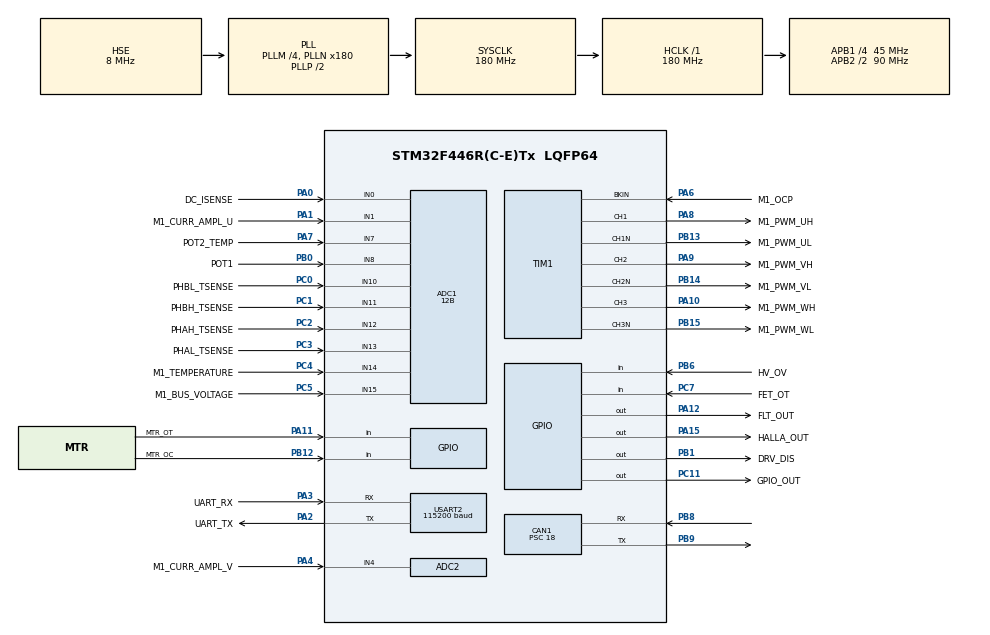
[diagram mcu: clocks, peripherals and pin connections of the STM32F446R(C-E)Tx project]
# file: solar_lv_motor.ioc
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ADC1.Channel-1\#ChannelInjectedConversion=ADC_CHANNEL_1
ADC1.Channel-1\#ChannelRegularConversion=ADC_CHANNEL_15
ADC1.Channel-2\#ChannelRegularConversion=ADC_CHANNEL_14
ADC1.ClockPrescaler=ADC_CLOCK_SYNC_PCLK_DIV4
ADC1.ContinuousConvMode=DISABLE
ADC1.DMAContinuousRequests=DISABLE
ADC1.DataAlign=ADC_DATAALIGN_LEFT
ADC1.DiscontinuousConvMode=DISABLE
ADC1.EOCSelection=ADC_EOC_SINGLE_CONV
ADC1.EnableAnalogWatchDog=false
ADC1.ExternalTrigConv=ADC_SOFTWARE_START
ADC1.ExternalTrigConvEdge=ADC_EXTERNALTRIGCONVEDGE_NONE
ADC1.ExternalTrigInjecConv=ADC_EXTERNALTRIGINJECCONV_T1_CC4
ADC1.ExternalTrigInjecConvEdge=ADC_EXTERNALTRIGINJECCONVEDGE_RISING
ADC1.InjNumberOfConversion=1
ADC1.InjectedConvMode=None
ADC1.InjectedOffset-1\#ChannelInjectedConversion=0
ADC1.InjectedRank-1\#ChannelInjectedConversion=1
ADC1.NbrOfConversion=2
ADC1.NbrOfConversionFlag=1
ADC1.Rank-1\#ChannelRegularConversion=1
ADC1.Rank-2\#ChannelRegularConversion=2
ADC1.Resolution=ADC_RESOLUTION_12B
ADC1.SamplingTime-1\#ChannelInjectedConversion=ADC_SAMPLETIME_15CYCLES
ADC1.SamplingTime-1\#ChannelRegularConversion=ADC_SAMPLETIME_3CYCLES
ADC1.SamplingTime-2\#ChannelRegularConversion=ADC_SAMPLETIME_28CYCLES
ADC1.ScanConvMode=ENABLE
ADC1.master=1
ADC2.Channel-1\#ChannelInjectedConversion=ADC_CHANNEL_4
ADC2.Channel-1\#ChannelRegularConversion=ADC_CHANNEL_4
ADC2.ClockPrescaler=ADC_CLOCK_SYNC_PCLK_DIV4
ADC2.ContinuousConvMode=DISABLE
ADC2.DMAContinuousRequests=DISABLE
ADC2.DataAlign=ADC_DATAALIGN_LEFT
ADC2.DiscontinuousConvMode=DISABLE
ADC2.EOCSelection=ADC_EOC_SINGLE_CONV
ADC2.EnableAnalogWatchDog=false
ADC2.ExternalTrigConv=ADC_SOFTWARE_START
ADC2.ExternalTrigConvEdge=ADC_EXTERNALTRIGCONVEDGE_NONE
ADC2.ExternalTrigInjecConv=ADC_EXTERNALTRIGINJECCONV_T1_CC4
ADC2.ExternalTrigInjecConvEdge=ADC_EXTERNALTRIGINJECCONVEDGE_RISING
ADC2.InjNumberOfConversion=1
ADC2.InjectedConvMode=None
ADC2.InjectedOffset-1\#ChannelInjectedConversion=0
ADC2.InjectedRank-1\#ChannelInjectedConversion=1
ADC2.NbrOfConversion=1
ADC2.NbrOfConversionFlag=1
ADC2.Rank-1\#ChannelRegularConversion=1
ADC2.Resolution=ADC_RESOLUTION_12B
ADC2.SamplingTime-1\#ChannelInjectedConversion=ADC_SAMPLETIME_15CYCLES
ADC2.SamplingTime-1\#ChannelRegularConversion=ADC_SAMPLETIME_15CYCLES
ADC2.ScanConvMode=ENABLE
CAN1.BS1=CAN_BS1_2TQ
CAN1.BS2=CAN_BS2_2TQ
CAN1.CalculateBaudRate=500000
CAN1.CalculateTimeBit=2000
CAN1.CalculateTimeQuantum=400.0
CAN1.Mode=CAN_MODE_NORMAL
CAN1.NART=DISABLE
CAN1.Prescaler=18
ExtraMW=MotorControl
ExtraMW.MotorControl.Config=MotorControl
ExtraMW.MotorControl.Mode=MotorControl
ExtraMW.MotorControl.Root=MCSDK_v5.4.8/MotorControl
ExtraMW.MotorControl.Template=templates
Mcu.Family=STM32F4
Mcu.Name=STM32F446R(C-E)Tx
Mcu.Package=LQFP64
MotorControl.ADC_1_PERIPH=ADC1
MotorControl.ADC_2_PERIPH=ADC2
MotorControl.ADC_AHBPERIPH=RCC_AHBPeriph_ADC12
MotorControl.ADC_CLOCK_WB_DIV=1
MotorControl.ADC_CLOCK_WB_FREQ=22.5
MotorControl.ADC_PERIPH=ADC1
MotorControl.ADC_REFERENCE_VOLTAGE=3.30
MotorControl.ALIGNMENT_ANGLE_DEG=90
MotorControl.ALIGNMENT_DURATION=700
MotorControl.AMPLIFICATION_GAIN=0.077
MotorControl.ANGC={0,0,0,0,0,0,0,0}
MotorControl.BEMF_CONSISTENCY_GAIN=64
MotorControl.BEMF_CONSISTENCY_TOL=64
MotorControl.BKIN1_FILTER=0
MotorControl.BKIN2_FILTER=0
MotorControl.BKIN2_MODE=NONE
MotorControl.BKIN_MODE=EXT_MODE
MotorControl.BOARD=CUSTOM
MotorControl.BRKIN2_GPIO_AF=GPIO_AF_2
MotorControl.BRKIN_GPIO_AF=GPIO_AF_2
MotorControl.BUS_VOLTAGE_READING=true
MotorControl.CCMRAM_ENABLED=false
MotorControl.CLOCK_FREQUENCY=CPU_CLK_180_MHZ
MotorControl.CLOCK_SOURCE=EXTERNAL
MotorControl.CONSTANT1_D=217251
MotorControl.CONSTANT1_Q=217251
MotorControl.CONSTANT2_QD=79808
MotorControl.CORD_BEMF_CONSISTENCY_GAIN=64
MotorControl.CORD_BEMF_CONSISTENCY_TOL=64
MotorControl.CORD_F1=16384
MotorControl.CORD_F2=8192
MotorControl.CORD_FIFO_DEPTH_01HZ=64
MotorControl.CORD_FIFO_DEPTH_DPP=64
MotorControl.CORD_GAIN1=-24009
MotorControl.CORD_GAIN2=16293
MotorControl.CORD_MAX_ACCEL_DPPP=39
MotorControl.CORD_MEAS_ERRORS_BEFORE_FAULTS=5
MotorControl.CORD_VARIANCE_THRESHOLD=4
MotorControl.CPU_CLK_180_MHZ=true
MotorControl.CTRBDID=0
MotorControl.CUBE_MX_VER=6.6.0
MotorControl.CURRENT_READING_TOPOLOGY=ICS_SENSORS
MotorControl.CURR_SAMPLING_TIME=15
MotorControl.DAC_EMULATED=false
MotorControl.DAC_FUNCTIONALITY=false
MotorControl.DAC_TIMER_CH1_GPIO_PIN=LL_GPIO_PIN_0
MotorControl.DAC_TIMER_CH1_GPIO_PORT=GPIOA
MotorControl.DAC_TIMER_CH2_GPIO_PIN=LL_GPIO_PIN_0
MotorControl.DAC_TIMER_CH2_GPIO_PORT=GPIOA
MotorControl.DAC_TIMER_SELECTION=TIM3
MotorControl.DC_CURRENT_RS_MEAS=8.00
MotorControl.DEBUG_DAC_CH1=false
MotorControl.DEBUG_DAC_CH2=false
MotorControl.DEFAULT_CONTROL_MODE=STC_TORQUE_MODE
MotorControl.DEFAULT_DAC_CHANNEL_1=MC_PROTOCOL_REG_MEAS_ROT_SPEED
MotorControl.DEFAULT_DAC_CHANNEL_2=MC_PROTOCOL_REG_MEAS_ROT_SPEED
MotorControl.DEFAULT_DAC_MOTOR=0
MotorControl.DEFAULT_FLUX_COMPONENT=0
MotorControl.DEFAULT_TARGET_SPEED_RPM=1500
MotorControl.DEFAULT_TORQUE_COMPONENT=0
MotorControl.DISSIPATIVE_BRAKE_POLARITY=DOUT_ACTIVE_HIGH
MotorControl.DRIVES_NUMBER_SELECTION=SINGLEDRIVE
MotorControl.EMERGENCY2_STOP_GPIO_PIN=LL_GPIO_PIN_6
MotorControl.EMERGENCY2_STOP_GPIO_PORT=GPIOA
MotorControl.EMERGENCY_STOP_GPIO_PIN=LL_GPIO_PIN_6
MotorControl.EMERGENCY_STOP_GPIO_PORT=GPIOA
MotorControl.ENABLE_SL_ALGO_FROM_PHASE=1
MotorControl.ENCODER_AVAILABLE=false
MotorControl.ENCODER_PPR=400
MotorControl.ENC_AVERAGING_FIFO_DEPTH=16
MotorControl.ENC_A_GPIO_PIN=LL_GPIO_PIN_0
MotorControl.ENC_A_GPIO_PORT=GPIOA
MotorControl.ENC_B_GPIO_PIN=LL_GPIO_PIN_3
MotorControl.ENC_B_GPIO_PORT=GPIOB
MotorControl.ENC_ICx_FILTER=64
MotorControl.ENC_INVERT_SPEED=false
MotorControl.ENC_MEAS_ERRORS_BEFORE_FAULTS=5
MotorControl.ENC_TIMER_REMAPPING=NO_REMAP_TIM2
MotorControl.ENC_TIMER_SELECTION=ENC_TIM2
MotorControl.ENC_USE_CH3=false
MotorControl.EXT_CLK_8_MHZ=true
MotorControl.EXT_CLOCK_FREQUENCY=EXT_CLK_8_MHZ
MotorControl.F1=16384
MotorControl.F2=8192
MotorControl.FEEDBACK_NET_FILTERING=false
MotorControl.FEED_FORWARD_CURRENT_REG_ENABLING=false
MotorControl.FINAL_I_ALIGNMENT=2981
MotorControl.FLUX_WEAKENING_ENABLING=false
MotorControl.FW_KIDIV=32768
MotorControl.FW_KI_GAIN=5000
MotorControl.FW_KPDIV=32768
MotorControl.FW_KP_GAIN=3000
MotorControl.FW_VOLTAGE_REF=985
MotorControl.GAIN1=-24009
MotorControl.GAIN2=16293
MotorControl.H1_GPIO_PIN=LL_GPIO_PIN_15
MotorControl.H1_GPIO_PORT=GPIOA
MotorControl.H2_GPIO_PIN=LL_GPIO_PIN_3
MotorControl.H2_GPIO_PORT=GPIOB
MotorControl.H3_GPIO_PIN=LL_GPIO_PIN_10
MotorControl.H3_GPIO_PORT=GPIOB
MotorControl.HALL_AVERAGING_FIFO_DEPTH=6
MotorControl.HALL_ICx_FILTER=128
MotorControl.HALL_MEAS_ERRORS_BEFORE_FAULTS=5
MotorControl.HALL_MTPA=false
MotorControl.HALL_PHASE_SHIFT=0
MotorControl.HALL_SENSORS_AVAILABLE=true
MotorControl.HALL_SENSORS_PLACEMENT=DEGREES_120
MotorControl.HALL_TIMER_REMAPPING=NO_REMAP_TIM2
MotorControl.HALL_TIMER_SELECTION=HALL_TIM2
MotorControl.HFI_AMPLITUDE=25
MotorControl.HFI_DC_0_COEFF=0.00146
MotorControl.HFI_DC_1_COEFF=0.002921
MotorControl.HFI_DC_2_COEFF=0.00146
MotorControl.HFI_DC_3_COEFF=1.889033
MotorControl.HFI_DC_4_COEFF=-0.894874
MotorControl.HFI_DEBUG_MODE=false
MotorControl.HFI_FREQUENCY=400
MotorControl.HFI_HIFRAMPLSCAN=25
MotorControl.HFI_HP_ID_0_COEFF=0.939693
MotorControl.HFI_HP_ID_1_COEFF=-1.879386
MotorControl.HFI_HP_ID_2_COEFF=0.939693
MotorControl.HFI_HP_ID_3_COEFF=1.875746
MotorControl.HFI_HP_ID_4_COEFF=-0.883026
MotorControl.HFI_IDH_DELAY=32400
MotorControl.HFI_LOCKFREQ=33
MotorControl.HFI_LP_ID_0_COEFF=0.00597
MotorControl.HFI_LP_ID_1_COEFF=0.011941
MotorControl.HFI_LP_ID_2_COEFF=0.00597
MotorControl.HFI_LP_ID_3_COEFF=1.769837
MotorControl.HFI_LP_ID_4_COEFF=-0.793719
MotorControl.HFI_MAXANGLEDIFF=3640
MotorControl.HFI_MINIMUM_SPEED_RPM=402
MotorControl.HFI_NOTCH_IQD_0_COEFF=0.969619
MotorControl.HFI_NOTCH_IQD_1_COEFF=-1.923946
MotorControl.HFI_NOTCH_IQD_2_COEFF=0.969619
MotorControl.HFI_NOTCH_IQD_3_COEFF=1.923946
MotorControl.HFI_NOTCH_IQD_4_COEFF=-0.939237
MotorControl.HFI_NSDETPOINTSSKIP=10
MotorControl.HFI_NSMAXDETPOINTS=20
MotorControl.HFI_NS_MIN_SAT_DIFF=0
MotorControl.HFI_PID_KIDIV=32768
MotorControl.HFI_PID_KI_DEFAULT=400
MotorControl.HFI_PID_KPDIV=16384
MotorControl.HFI_PID_KP_DEFAULT=800
MotorControl.HFI_PLL_KI_DEFAULT=0.00400
MotorControl.HFI_PLL_KP_DEFAULT=0.00060
MotorControl.HFI_RESTARTTIMESEC=0.1
MotorControl.HFI_RESTART_RPM_TH=(((HFI_STO_RPM_TH)+(STO_HFI_RPM_TH))/2)
MotorControl.HFI_REVERT_DIRECTION=true
MotorControl.HFI_SCANROTATIONSNO=3
MotorControl.HFI_SPD_BUFFER_DEPTH_01HZ=64
MotorControl.HFI_STEPANGLE=3640
MotorControl.HFI_STO_RPM_TH=OBS_MINIMUM_SPEED_RPM
MotorControl.HFI_WAITAFTERNS2=4
MotorControl.HFI_WAITBEFORESN=6
MotorControl.HFI_WAITSYNCH=20
MotorControl.HFI_WAITTRACK=20
MotorControl.HIGH_SIDE_BRAKE_STATE=false
MotorControl.HIGH_SIDE_IDLE_STATE=false
MotorControl.HW_COMPLEMENTED_LOW_SIDE=false
MotorControl.HW_DEAD_TIME_NS=100
MotorControl.HW_OV_CURRENT_PROT_BYPASS=false
MotorControl.ICS_SENSORS=true
MotorControl.ID_DEMAG=-12233
MotorControl.INRUSH_CURRLIMIT_AT_POWER_ON=true
MotorControl.INRUSH_CURRLIMIT_CHANGE_AFTER_MS=1000
MotorControl.INRUSH_CURRLIMIT_ENABLING=false
MotorControl.INRUSH_CURRLIMIT_GPIO_PIN=LL_GPIO_PIN_4
MotorControl.INRUSH_CURRLIMIT_GPIO_PORT=GPIOE
MotorControl.INRUSH_CURR_LIMITER_POLARITY=DOUT_ACTIVE_HIGH
MotorControl.INTERNAL_OVERCURRENTPROTECTION=false
MotorControl.INTERNAL_OVERVOLTAGEPROTECTION=false
MotorControl.IPs=NVIC,RCC,SYS,MotorControl,TIM1,ADC1,ADC2,TIM2,DAC,USART2
MotorControl.IQMAX=12233
MotorControl.LCD_JOYSTICK_FUNCTIONALITY=false
MotorControl.LCD_MODE=LCD_FULL
MotorControl.LDLQ_RATIO=1.000
MotorControl.LOW_SIDE_BRAKE_STATE=false
MotorControl.LOW_SIDE_IDLE_STATE=false
MotorControl.LOW_SIDE_SIGNALS_ENABLING=LS_PWM_TIMER
MotorControl.LS=0.000130
MotorControl.MAX_APPLICATION_SPEED=4000
MotorControl.MAX_MODULATION_100_PER_CENT=true
MotorControl.MAX_MODULATION_INDEX=MAX_MODULATION_100_PER_CENT
MotorControl.MCU=STM32F446RE
MotorControl.MCU_TYPE=STM32F446xC_xE
MotorControl.MC_WORKBENCH_VERSION=5.4.8.21553
MotorControl.MEAS_ERRORS_BEFORE_FAULTS=5
MotorControl.MIN_APPLICATION_SPEED=0
MotorControl.MOTOR_MAX_SPEED_RPM=4000
MotorControl.MOTOR_TYPE=PMSM
MotorControl.MOTOR_VOLTAGE_CONSTANT=4.2
MotorControl.MTPA_ENABLING=false
MotorControl.NB_CONSECUTIVE_TESTS=2
MotorControl.NOMINAL_BUS_VOLTAGE_V=24
MotorControl.NOMINAL_CURRENT=12233
MotorControl.OBS_MEAS_ERRORS_BEFORE_FAULTS=5
MotorControl.OBS_MINIMUM_SPEED_RPM=450
MotorControl.OCPA_INVERTINGINPUT=COMPX_InvertingInput_VREF
MotorControl.OCPA_INVERTINGINPUT_GPIO_PIN=LL_GPIO_PIN_4
MotorControl.OCPA_INVERTINGINPUT_GPIO_PORT=GPIOA
MotorControl.OCPA_INVERTINGINPUT_MODE=INT_MODE
MotorControl.OCPA_NONINVERTINGINPUT=COMP1_NonInvertingInput_PA1
MotorControl.OCPA_NONINVERTINGINPUT_GPIO_PIN=LL_GPIO_PIN_1
MotorControl.OCPA_NONINVERTINGINPUT_GPIO_PORT=GPIOA
MotorControl.OCPA_OUTPUT=COMP_Output_TIM1BKIN2
MotorControl.OCPA_OUTPUTPOL=COMP_OutputPol_NonInverted
MotorControl.OCPA_OUTPUT_GPIO_AF=GPIO_AF_8
MotorControl.OCPA_OUTPUT_GPIO_PIN=LL_GPIO_PIN_0
MotorControl.OCPA_OUTPUT_GPIO_PORT=GPIOA
MotorControl.OCPA_OUTPUT_MODE=INT_MODE
MotorControl.OCPA_SELECTION=COMP1
MotorControl.OCPB_INVERTINGINPUT=COMPX_InvertingInput_VREF
MotorControl.OCPB_INVERTINGINPUT_GPIO_PIN=LL_GPIO_PIN_4
MotorControl.OCPB_INVERTINGINPUT_GPIO_PORT=GPIOA
MotorControl.OCPB_INVERTINGINPUT_MODE=INT_MODE
MotorControl.OCPB_NONINVERTINGINPUT=COMP2_NonInvertingInput_PA7
MotorControl.OCPB_NONINVERTINGINPUT_GPIO_PIN=LL_GPIO_PIN_7
MotorControl.OCPB_NONINVERTINGINPUT_GPIO_PORT=GPIOA
MotorControl.OCPB_OUTPUT=COMP_Output_TIM1BKIN2
MotorControl.OCPB_OUTPUTPOL=COMP_OutputPol_NonInverted
MotorControl.OCPB_OUTPUT_GPIO_AF=GPIO_AF_8
MotorControl.OCPB_OUTPUT_GPIO_PIN=LL_GPIO_PIN_2
MotorControl.OCPB_OUTPUT_GPIO_PORT=GPIOA
MotorControl.OCPB_OUTPUT_MODE=INT_MODE
MotorControl.OCPB_SELECTION=COMP2
MotorControl.OCPC_INVERTINGINPUT=COMPX_InvertingInput_VREF
MotorControl.OCPC_INVERTINGINPUT_GPIO_PIN=LL_GPIO_PIN_4
MotorControl.OCPC_INVERTINGINPUT_GPIO_PORT=GPIOA
MotorControl.OCPC_INVERTINGINPUT_MODE=INT_MODE
MotorControl.OCPC_NONINVERTINGINPUT=COMP3_NonInvertingInput_PD14
MotorControl.OCPC_NONINVERTINGINPUT_GPIO_PIN=LL_GPIO_PIN_14
MotorControl.OCPC_NONINVERTINGINPUT_GPIO_PORT=GPIOD
MotorControl.OCPC_OUTPUT=COMP_Output_TIM1BKIN2
MotorControl.OCPC_OUTPUTPOL=COMP_OutputPol_NonInverted
MotorControl.OCPC_OUTPUT_GPIO_AF=GPIO_AF_7
MotorControl.OCPC_OUTPUT_GPIO_PIN=LL_GPIO_PIN_8
MotorControl.OCPC_OUTPUT_GPIO_PORT=GPIOC
MotorControl.OCPC_OUTPUT_MODE=INT_MODE
MotorControl.OCPC_SELECTION=COMP3
MotorControl.OCPREF=23830
MotorControl.OCP_COMP_THRESHOLD=2.27
MotorControl.OCP_FILTER=COMP_Mode_HighSpeed
MotorControl.OCP_INVERTINGINPUT=COMPX_InvertingInput_VREF
MotorControl.OCP_INVERTINGINPUT_GPIO_PIN=LL_GPIO_PIN_4
MotorControl.OCP_INVERTINGINPUT_GPIO_PORT=GPIOA
MotorControl.OCP_INVERTINGINPUT_MODE=INT_MODE
MotorControl.OCP_NONINVERTINGINPUT=COMP2_NonInvertingInput_PA7
MotorControl.OCP_NONINVERTINGINPUT_GPIO_PIN=LL_GPIO_PIN_7
MotorControl.OCP_NONINVERTINGINPUT_GPIO_PORT=GPIOA
MotorControl.OCP_OUTPUT=COMP_Output_TIM1BKIN2
MotorControl.OCP_OUTPUTPOL=COMP_OutputPol_NonInverted
MotorControl.OCP_OUTPUT_GPIO_AF=GPIO_AF_8
MotorControl.OCP_OUTPUT_GPIO_PIN=LL_GPIO_PIN_2
MotorControl.OCP_OUTPUT_GPIO_PORT=GPIOA
MotorControl.OCP_OUTPUT_MODE=INT_MODE
MotorControl.OCP_SELECTION=COMP2
MotorControl.OFST={0,0,0,0,0,0,0,0}
MotorControl.ON_OVER_VOLTAGE=TURN_OFF_PWM
MotorControl.OPAMP1_INVERTINGINPUT=OPAMP1_InvertingInput_PGA
MotorControl.OPAMP1_INVERTINGINPUT_GPIO_PIN=LL_GPIO_PIN_3
MotorControl.OPAMP1_INVERTINGINPUT_GPIO_PORT=GPIOA
MotorControl.OPAMP1_INVERTINGINPUT_MODE=INT_MODE
MotorControl.OPAMP1_NONINVERTINGINPUT_PHA=OPAMP1_NonInvertingInput_PA1
MotorControl.OPAMP1_NONINVERTINGINPUT_PHA_GPIO_PIN=LL_GPIO_PIN_1
MotorControl.OPAMP1_NONINVERTINGINPUT_PHA_GPIO_PORT=GPIOA
MotorControl.OPAMP1_NONINVERTINGINPUT_PHB=OPAMP1_NonInvertingInput_PA7
MotorControl.OPAMP1_NONINVERTINGINPUT_PHB_GPIO_PIN=LL_GPIO_PIN_7
MotorControl.OPAMP1_NONINVERTINGINPUT_PHB_GPIO_PORT=GPIOA
MotorControl.OPAMP1_OUT_GPIO_PIN=LL_GPIO_PIN_2
MotorControl.OPAMP1_OUT_GPIO_PORT=GPIOA
MotorControl.OPAMP1_SELECTION=OPAMP1
MotorControl.OPAMP2_INVERTINGINPUT=OPAMP2_InvertingInput_PGA
MotorControl.OPAMP2_INVERTINGINPUT_GPIO_PIN=LL_GPIO_PIN_5
MotorControl.OPAMP2_INVERTINGINPUT_GPIO_PORT=GPIOC
MotorControl.OPAMP2_INVERTINGINPUT_MODE=INT_MODE
MotorControl.OPAMP2_NONINVERTINGINPUT_PHA=OPAMP2_NonInvertingInput_PB14
MotorControl.OPAMP2_NONINVERTINGINPUT_PHA_GPIO_PIN=LL_GPIO_PIN_14
MotorControl.OPAMP2_NONINVERTINGINPUT_PHA_GPIO_PORT=GPIOB
MotorControl.OPAMP2_NONINVERTINGINPUT_PHB=OPAMP2_NonInvertingInput_PA7
MotorControl.OPAMP2_NONINVERTINGINPUT_PHB_GPIO_PIN=LL_GPIO_PIN_7
MotorControl.OPAMP2_NONINVERTINGINPUT_PHB_GPIO_PORT=GPIOA
MotorControl.OPAMP2_NONINVERTINGINPUT_PHC=OPAMP2_NonInvertingInput_PB14
MotorControl.OPAMP2_NONINVERTINGINPUT_PHC_GPIO_PIN=LL_GPIO_PIN_14
MotorControl.OPAMP2_NONINVERTINGINPUT_PHC_GPIO_PORT=GPIOB
MotorControl.OPAMP2_OUT_GPIO_PIN=LL_GPIO_PIN_6
MotorControl.OPAMP2_OUT_GPIO_PORT=GPIOA
MotorControl.OPAMP2_SELECTION=OPAMP2
MotorControl.OPAMP3_INVERTINGINPUT=OPAMP1_InvertingInput_PGA
MotorControl.OPAMP3_INVERTINGINPUT_GPIO_PIN=LL_GPIO_PIN_0
MotorControl.OPAMP3_INVERTINGINPUT_GPIO_PORT=GPIOA
MotorControl.OPAMP3_INVERTINGINPUT_MODE=INT_MODE
MotorControl.OPAMP3_SELECTION=OPAMP1
MotorControl.OPAMP_INVERTINGINPUT=OPAMP1_InvertingInput_PGA
MotorControl.OPAMP_INVERTINGINPUT_GPIO_PIN=LL_GPIO_PIN_3
MotorControl.OPAMP_INVERTINGINPUT_GPIO_PORT=GPIOA
MotorControl.OPAMP_INVERTINGINPUT_MODE=INT_MODE
MotorControl.OPAMP_NONINVERTINGINPUT=OPAMP1_NonInvertingInput_PA7
MotorControl.OPAMP_NONINVERTINGINPUT_GPIO_PIN=LL_GPIO_PIN_7
MotorControl.OPAMP_NONINVERTINGINPUT_GPIO_PORT=GPIOA
MotorControl.OPAMP_OUT_GPIO_PIN=LL_GPIO_PIN_2
MotorControl.OPAMP_OUT_GPIO_PORT=GPIOA
MotorControl.OPAMP_PGACONNECT=OPAMP_PGAConnect_No
MotorControl.OPAMP_PGAGAIN=OPAMP_OPAMP_PGAGain_2
MotorControl.OPAMP_SELECTION=OPAMP1
MotorControl.OPAMP_TYPE_GAIN=INTERNAL
MotorControl.OPEN_LOOP_FOC=false
MotorControl.OPEN_LOOP_K=44
MotorControl.OPEN_LOOP_OFF=4400
MotorControl.OPEN_LOOP_SPEED_RAMP_DURATION_MS=1000
MotorControl.OPEN_LOOP_SPEED_RPM=100
MotorControl.OPEN_LOOP_VF=false
MotorControl.OPEN_LOOP_VOLTAGE_d=6000
MotorControl.OTF_STARTUP=true
MotorControl.OVERCURR_FEEDBACK_POLARITY=EMSTOP_ACTIVE_HIGH
MotorControl.OVERCURR_PROTECTION_HW_DISABLING=DOUT_ACTIVE_HIGH
MotorControl.OVPREF=23830
MotorControl.OVP_FILTER=COMP_Mode_HighSpeed
MotorControl.OVP_INVERTINGINPUT=COMPX_InvertingInput_VREF
MotorControl.OVP_INVERTINGINPUT_GPIO_PIN=LL_GPIO_PIN_4
MotorControl.OVP_INVERTINGINPUT_GPIO_PORT=GPIOA
MotorControl.OVP_INVERTINGINPUT_MODE=INT_MODE
MotorControl.OVP_NONINVERTINGINPUT=COMP7_NonInvertingInput_PA0
MotorControl.OVP_NONINVERTINGINPUT_GPIO_PIN=LL_GPIO_PIN_0
MotorControl.OVP_NONINVERTINGINPUT_GPIO_PORT=GPIOA
MotorControl.OVP_OUTPUT=COMP_Output_TIM1BKIN
MotorControl.OVP_OUTPUTPOL=COMP_OutputPol_NonInverted
MotorControl.OVP_OUTPUT_GPIO_AF=GPIO_AF_3
MotorControl.OVP_OUTPUT_GPIO_PIN=LL_GPIO_PIN_2
MotorControl.OVP_OUTPUT_GPIO_PORT=GPIOC
MotorControl.OVP_OUTPUT_MODE=INT_MODE
MotorControl.OVP_SELECTION=COMP7
MotorControl.OV_CURR_BYPASS_GPIO_PIN=LL_GPIO_PIN_5
MotorControl.OV_CURR_BYPASS_GPIO_PORT=GPIOE
MotorControl.OV_TEMPERATURE_HYSTERESIS_C=10
MotorControl.OV_TEMPERATURE_PROT_ENABLING=false
MotorControl.OV_TEMPERATURE_THRESHOLD_C=125
MotorControl.OV_VOLTAGE_PROT_ENABLING=true
MotorControl.OV_VOLTAGE_THRESHOLD_V=28
MotorControl.PHASE1_DURATION=250
MotorControl.PHASE1_FINAL_CURRENT=0
MotorControl.PHASE1_FINAL_SPEED_RPM=0
MotorControl.PHASE2_DURATION=250
MotorControl.PHASE2_FINAL_CURRENT=0
MotorControl.PHASE2_FINAL_SPEED_RPM=0
MotorControl.PHASE3_DURATION=0
MotorControl.PHASE3_FINAL_CURRENT=458
MotorControl.PHASE3_FINAL_SPEED_RPM=0
MotorControl.PHASE4_DURATION=1000
MotorControl.PHASE4_FINAL_CURRENT=6804
MotorControl.PHASE4_FINAL_SPEED_RPM=300
MotorControl.PHASE5_DURATION=2000
MotorControl.PHASE5_FINAL_CURRENT=6804
MotorControl.PHASE5_FINAL_SPEED_RPM=900
MotorControl.PHASE_CURRENTS_ADC=ADC1_2
MotorControl.PHASE_CURRENTS_CHANNEL=ADC_CHANNEL_9
MotorControl.PHASE_CURRENTS_GPIO_PIN=LL_GPIO_PIN_1
MotorControl.PHASE_CURRENTS_GPIO_PORT=GPIOB
MotorControl.PHASE_UH_GPIO_AF=GPIO_AF_6
MotorControl.PHASE_UH_GPIO_PIN=LL_GPIO_PIN_8
MotorControl.PHASE_UH_GPIO_PORT=GPIOA
MotorControl.PHASE_UH_POLARITY=H_ACTIVE_HIGH
MotorControl.PHASE_UL_GPIO_AF=GPIO_AF_6
MotorControl.PHASE_UL_GPIO_PIN=LL_GPIO_PIN_13
MotorControl.PHASE_UL_GPIO_PORT=GPIOB
MotorControl.PHASE_UL_POLARITY=L_ACTIVE_HIGH
MotorControl.PHASE_U_CURR_ADC=ADC123
MotorControl.PHASE_U_CURR_CHANNEL=ADC_CHANNEL_1
MotorControl.PHASE_U_GPIO_PIN=LL_GPIO_PIN_1
MotorControl.PHASE_U_GPIO_PORT=GPIOA
MotorControl.PHASE_VH_GPIO_AF=GPIO_AF_6
MotorControl.PHASE_VH_GPIO_PIN=LL_GPIO_PIN_9
MotorControl.PHASE_VH_GPIO_PORT=GPIOA
MotorControl.PHASE_VH_POLARITY=H_ACTIVE_HIGH
MotorControl.PHASE_VL_GPIO_AF=GPIO_AF_6
MotorControl.PHASE_VL_GPIO_PIN=LL_GPIO_PIN_14
MotorControl.PHASE_VL_GPIO_PORT=GPIOB
MotorControl.PHASE_VL_POLARITY=L_ACTIVE_HIGH
MotorControl.PHASE_V_CURR_ADC=ADC1_2
MotorControl.PHASE_V_CURR_CHANNEL=ADC_CHANNEL_4
MotorControl.PHASE_V_GPIO_PIN=LL_GPIO_PIN_4
MotorControl.PHASE_V_GPIO_PORT=GPIOA
MotorControl.PHASE_WH_GPIO_AF=GPIO_AF_6
MotorControl.PHASE_WH_GPIO_PIN=LL_GPIO_PIN_10
MotorControl.PHASE_WH_GPIO_PORT=GPIOA
MotorControl.PHASE_WH_POLARITY=H_ACTIVE_HIGH
MotorControl.PHASE_WL_GPIO_AF=GPIO_AF_4
MotorControl.PHASE_WL_GPIO_PIN=LL_GPIO_PIN_15
MotorControl.PHASE_WL_GPIO_PORT=GPIOB
MotorControl.PHASE_WL_POLARITY=L_ACTIVE_HIGH
MotorControl.PHASE_W_CURR_ADC=ADC1_2
MotorControl.PHASE_W_CURR_CHANNEL=ADC_CHANNEL_6
MotorControl.PHASE_W_GPIO_PIN=LL_GPIO_PIN_6
MotorControl.PHASE_W_GPIO_PORT=GPIOA
MotorControl.PID_FLUX_KD_DEFAULT=100
MotorControl.PID_FLUX_KI_DEFAULT=2107
MotorControl.PID_FLUX_KP_DEFAULT=2853
MotorControl.PID_SPEED_KD_DEFAULT=0
MotorControl.PID_SPEED_KI_DEFAULT=2972
MotorControl.PID_SPEED_KP_DEFAULT=2073
MotorControl.PID_TORQUE_KD_DEFAULT=100
MotorControl.PID_TORQUE_KI_DEFAULT=2107
MotorControl.PID_TORQUE_KP_DEFAULT=2853
MotorControl.PLL_KI_GAIN=15
MotorControl.PLL_KP_GAIN=426
MotorControl.POLE_PAIR_NUM=4
MotorControl.POSITION_CTRL_ENABLING=false
MotorControl.PWBDID=0
MotorControl.PWM_FREQUENCY=20000
MotorControl.PWM_TIMER_REMAPPING=PWM_NO_REMAP
MotorControl.PWM_TIMER_SELECTION=PWM_TIM1
MotorControl.REGCONVADC=ADC1
MotorControl.REGULATION_EXECUTION_RATE=1
MotorControl.RS=0.12
MotorControl.RSHUNT=0.22000
MotorControl.RTOS=NONE
MotorControl.R_BRAKE_GPIO_PIN=LL_GPIO_PIN_5
MotorControl.R_BRAKE_GPIO_PORT=GPIOE
MotorControl.R_BRAKE_SWITCH_OFF_THRES_V=22
MotorControl.SEGDIV=0
MotorControl.SERIAL_COMMUNICATION=true
MotorControl.SERIAL_COM_CHANNEL1=MC_PROTOCOL_REG_I_A
MotorControl.SERIAL_COM_CHANNEL2=MC_PROTOCOL_REG_I_A
MotorControl.SERIAL_COM_MODE=COM_BIDIRECTIONAL
MotorControl.SERIAL_COM_MOTOR=0
MotorControl.SHARED_SIGNAL_ENABLE=false
MotorControl.SINGLEDRIVE=true
MotorControl.SPD_DIFFERENTIAL_TERM_ENABLING=false
MotorControl.SPEED_BAND_LOWER_LIMIT=15
MotorControl.SPEED_BAND_UPPER_LIMIT=17
MotorControl.SPEED_LOOP_FREQUENCY_HZ=1000
MotorControl.SPEED_SENSOR_SELECTION=STATE_OBSERVER_PLL
MotorControl.SP_KDDIV=16
MotorControl.SP_KIDIV=16384
MotorControl.SP_KPDIV=16
MotorControl.STARTING_ANGLE_DEG=0
MotorControl.START_STOP_BTN=false
MotorControl.START_STOP_GPIO_PIN=LL_GPIO_PIN_6
MotorControl.START_STOP_GPIO_PORT=GPIOE
MotorControl.START_STOP_POLARITY=DIN_ACTIVE_LOW
MotorControl.START_STOP_POLARITY_EDGE=GPIO_NOPULL
MotorControl.STATE_OBSERVER_PLL=true
MotorControl.STM32F446xC_xE=true
MotorControl.STO_FIFO_DEPTH_01HZ=64
MotorControl.STO_FIFO_DEPTH_DPP=64
MotorControl.STO_HFI_RPM_TH=460
MotorControl.SW_DEADTIME_NS=800
MotorControl.SW_OV_CURRENT_PROT_ENABLING=true
MotorControl.T0_C=0
MotorControl.TEMPERATURE_READING=false
MotorControl.TEMP_ADC_SAMPLING_TIME=28
MotorControl.TEMP_FDBK_ADC=ADC1
MotorControl.TEMP_FDBK_CHANNEL=ADC_CHANNEL_14
MotorControl.TEMP_FDBK_GPIO_PIN=LL_GPIO_PIN_4
MotorControl.TEMP_FDBK_GPIO_PORT=GPIOC
MotorControl.TFDIFFERENTIAL_TERM_ENABLING=false
MotorControl.TF_KDDIV=8192
MotorControl.TF_KIDIV=16384
MotorControl.TF_KPDIV=1024
MotorControl.TNOISE_NS=2550
MotorControl.TRANSITION_DURATION=0
MotorControl.TRISE_NS=2550
MotorControl.T_MAX=125
MotorControl.UD_VOLTAGE_THRESHOLD_V=20
MotorControl.USART_REMAPPING=NO_REMAP_USART2
MotorControl.USART_RX_GPIO_PIN=LL_GPIO_PIN_3
MotorControl.USART_RX_GPIO_PORT=GPIOA
MotorControl.USART_SELECTION=USE_USART2
MotorControl.USART_SPEED=115200
MotorControl.USART_TX_GPIO_PIN=LL_GPIO_PIN_2
MotorControl.USART_TX_GPIO_PORT=GPIOA
MotorControl.USE_3OPAMPS=false
MotorControl.USE_INTERNAL_OPAMP=false
MotorControl.UV_VOLTAGE_PROT_ENABLING=false
MotorControl.V0_V=0.503
MotorControl.VARIANCE_THRESHOLD=0.1
MotorControl.VBUS_ADC=ADC1
MotorControl.VBUS_ADC_SAMPLING_TIME=3
MotorControl.VBUS_CHANNEL=ADC_CHANNEL_15
MotorControl.VBUS_GPIO_PIN=LL_GPIO_PIN_5
MotorControl.VBUS_GPIO_PORT=GPIOC
MotorControl.VBUS_PARTITIONING_FACTOR=0.1250
MotorControl.WB_to_Mx_template_version=21-11-15
MotorControl.WB_to_Mx_version=1.5.1
MotorControl.dV_dT=0.020
NVIC.ADC_IRQn=true\:2\:0\:true\:true\:false\:1\:false\:true\:true
NVIC.CAN1_RX0_IRQn=true\:0\:0\:false\:false\:true\:true\:true\:true
NVIC.PriorityGroup=NVIC_PRIORITYGROUP_3
NVIC.TIM1_BRK_TIM9_IRQn=true\:4\:1\:false\:true\:false\:3\:true\:true\:true
NVIC.TIM1_UP_TIM10_IRQn=true\:0\:0\:false\:true\:false\:2\:true\:true\:true
NVIC.TIM2_IRQn=true\:3\:0\:false\:true\:false\:4\:true\:true\:true
NVIC.USART2_IRQn=true\:3\:1\:true\:true\:false\:5\:true\:true\:true
PA0-WKUP.GPIO_Label=DC_ISENSE
PA0-WKUP.Signal=ADCx_IN0
PA1.GPIO_Label=M1_CURR_AMPL_U
PA1.Signal=ADCx_IN1
PA10.GPIO_Label=M1_PWM_WH
PA10.GPIO_PuPd=GPIO_PULLDOWN
PA10.GPIO_Speed=GPIO_SPEED_FREQ_HIGH
PA10.Signal=S_TIM1_CH3
PA11.GPIO_Label=MTR_OT
PA11.Signal=GPIO_Input
PA12.GPIO_Label=FLT_OUT
PA12.Signal=GPIO_Output
PA15.GPIO_Label=HALLA_OUT
PA15.Signal=GPIO_Output
PA2.GPIO_Label=UART_TX
PA2.GPIO_Mode=GPIO_MODE_AF_PP
PA2.GPIO_PuPd=GPIO_NOPULL
PA2.GPIO_Speed=GPIO_SPEED_FREQ_LOW
PA2.Mode=Asynchronous
PA2.Signal=USART2_TX
PA3.GPIO_Label=UART_RX
PA3.GPIO_Mode=GPIO_MODE_AF_PP
PA3.GPIO_PuPd=GPIO_NOPULL
PA3.GPIO_Speed=GPIO_SPEED_FREQ_LOW
PA3.Mode=Asynchronous
PA3.Signal=USART2_RX
PA4.GPIO_Label=M1_CURR_AMPL_V
PA4.Signal=ADCx_IN4
PA6.GPIO_Label=M1_OCP
PA6.GPIO_PuPd=GPIO_PULLDOWN
PA6.Mode=Activate-Break-Input
PA6.Signal=TIM1_BKIN
PA7.GPIO_Label=POT2_TEMP
PA7.Signal=ADCx_IN7
PA8.GPIO_Label=M1_PWM_UH
PA8.GPIO_PuPd=GPIO_PULLDOWN
PA8.GPIO_Speed=GPIO_SPEED_FREQ_HIGH
PA8.Signal=S_TIM1_CH1
PA9.GPIO_Label=M1_PWM_VH
PA9.GPIO_PuPd=GPIO_PULLDOWN
PA9.GPIO_Speed=GPIO_SPEED_FREQ_HIGH
PA9.Signal=S_TIM1_CH2
PB0.GPIO_Label=POT1
PB0.Signal=ADCx_IN8
PB1.GPIO_Label=DRV_DIS
PB1.Signal=GPIO_Output
PB12.GPIO_Label=MTR_OC
PB12.Signal=GPIO_Input
PB13.GPIO_Label=M1_PWM_UL
PB13.GPIO_PuPd=GPIO_PULLDOWN
PB13.GPIO_Speed=GPIO_SPEED_FREQ_HIGH
PB13.Mode=PWM Generation1 CH1 CH1N
PB13.Signal=TIM1_CH1N
PB14.GPIO_Label=M1_PWM_VL
PB14.GPIO_PuPd=GPIO_PULLDOWN
PB14.GPIO_Speed=GPIO_SPEED_FREQ_HIGH
PB14.Mode=PWM Generation2 CH2 CH2N
PB14.Signal=TIM1_CH2N
PB15.GPIO_Label=M1_PWM_WL
PB15.GPIO_PuPd=GPIO_PULLDOWN
PB15.GPIO_Speed=GPIO_SPEED_FREQ_HIGH
PB15.Mode=PWM Generation3 CH3 CH3N
PB15.Signal=TIM1_CH3N
PB6.GPIO_Label=HV_OV
PB6.Signal=GPIO_Input
PB8.Mode=CAN_Activate
PB8.Signal=CAN1_RX
PB9.Mode=CAN_Activate
PB9.Signal=CAN1_TX
PC0.GPIO_Label=PHBL_TSENSE
PC0.Signal=ADCx_IN10
PC1.GPIO_Label=PHBH_TSENSE
PC1.Signal=ADCx_IN11
PC11.GPIO_Label=GPIO_OUT
PC11.Signal=GPIO_Output
PC2.GPIO_Label=PHAH_TSENSE
PC2.Signal=ADCx_IN12
PC3.GPIO_Label=PHAL_TSENSE
PC3.Signal=ADCx_IN13
PC4.GPIO_Label=M1_TEMPERATURE
PC4.Signal=ADCx_IN14
PC5.GPIO_Label=M1_BUS_VOLTAGE
PC5.Signal=ADCx_IN15
PC7.GPIO_Label=FET_OT
PC7.Signal=GPIO_Input
PH0-OSC_IN.Mode=HSE-External-Oscillator
PH0-OSC_IN.Signal=RCC_OSC_IN
PH1-OSC_OUT.Mode=HSE-External-Oscillator
PH1-OSC_OUT.Signal=RCC_OSC_OUT
ProjectManager.HeapSize=0x200
ProjectManager.StackSize=0x400
ProjectManager.TargetToolchain=STM32CubeIDE
RCC.AHBFreq_Value=180000000
RCC.APB1CLKDivider=RCC_HCLK_DIV4
RCC.APB1Freq_Value=45000000
RCC.APB1TimFreq_Value=90000000
RCC.APB2CLKDivider=RCC_HCLK_DIV2
RCC.APB2Freq_Value=90000000
RCC.APB2TimFreq_Value=180000000
RCC.CortexFreq_Value=180000000
RCC.HCLKFreq_Value=180000000
RCC.HSE_VALUE=8000000
RCC.PLLM=4
RCC.PLLN=180
RCC.PLLSourceVirtual=RCC_PLLSOURCE_HSE
RCC.SYSCLKFreq_VALUE=180000000
RCC.SYSCLKSource=RCC_SYSCLKSOURCE_PLLCLK
RCC.USBFreq_Value=180000000
RCC.VCOOutputFreq_Value=360000000
SH.ADCx_IN0.0=ADC1_IN0,IN0
SH.ADCx_IN1.0=ADC1_IN1,IN1
SH.ADCx_IN10.0=ADC1_IN10,IN10
SH.ADCx_IN11.0=ADC1_IN11,IN11
SH.ADCx_IN12.0=ADC1_IN12,IN12
SH.ADCx_IN13.0=ADC1_IN13,IN13
SH.ADCx_IN14.0=ADC1_IN14,IN14
SH.ADCx_IN15.0=ADC1_IN15,IN15
SH.ADCx_IN4.0=ADC2_IN4,IN4
SH.ADCx_IN7.0=ADC1_IN7,IN7
SH.ADCx_IN8.0=ADC1_IN8,IN8
SH.S_TIM1_CH1.0=TIM1_CH1,PWM Generation1 CH1 CH1N
SH.S_TIM1_CH2.0=TIM1_CH2,PWM Generation2 CH2 CH2N
SH.S_TIM1_CH3.0=TIM1_CH3,PWM Generation3 CH3 CH3N
TIM1.BreakPolarity=TIM_BREAKPOLARITY_HIGH
TIM1.BreakState=TIM_BREAK_ENABLE
TIM1.Channel-PWM\ Generation1\ CH1\ CH1N=TIM_CHANNEL_1
TIM1.Channel-PWM\ Generation2\ CH2\ CH2N=TIM_CHANNEL_2
TIM1.Channel-PWM\ Generation3\ CH3\ CH3N=TIM_CHANNEL_3
TIM1.Channel-PWM\ Generation4\ No\ Output=TIM_CHANNEL_4
TIM1.ClockDivision=TIM_CLOCKDIVISION_DIV2
TIM1.CounterMode=TIM_COUNTERMODE_CENTERALIGNED1
TIM1.DeadTime=((DEAD_TIME_COUNTS) / 2)
TIM1.LockLevel=TIM_LOCKLEVEL_1
TIM1.OCIdleState_1=TIM_OCIDLESTATE_RESET
TIM1.OCIdleState_2=TIM_OCIDLESTATE_RESET
TIM1.OCIdleState_3=TIM_OCIDLESTATE_RESET
TIM1.OCMode_PWM-PWM\ Generation4\ No\ Output=TIM_OCMODE_PWM2
TIM1.OCNIdleState_1=TIM_OCNIDLESTATE_RESET
TIM1.OCNIdleState_2=TIM_OCNIDLESTATE_RESET
TIM1.OCNIdleState_3=TIM_OCNIDLESTATE_RESET
TIM1.OCNPolarity_1=TIM_OCNPOLARITY_HIGH
TIM1.OCNPolarity_2=TIM_OCNPOLARITY_HIGH
TIM1.OCNPolarity_3=TIM_OCNPOLARITY_HIGH
TIM1.OCPolarity_1=TIM_OCPOLARITY_HIGH
TIM1.OCPolarity_2=TIM_OCPOLARITY_HIGH
TIM1.OCPolarity_3=TIM_OCPOLARITY_HIGH
TIM1.OffStateIDLEMode=TIM_OSSI_ENABLE
TIM1.OffStateRunMode=TIM_OSSR_ENABLE
TIM1.Period=((PWM_PERIOD_CYCLES) / 2)
TIM1.Prescaler=((TIM_CLOCK_DIVIDER) - 1)
TIM1.Pulse-PWM\ Generation1\ CH1=((PWM_PERIOD_CYCLES) / 4)
TIM1.Pulse-PWM\ Generation2\ CH2=((PWM_PERIOD_CYCLES) / 4)
TIM1.Pulse-PWM\ Generation3\ CH3=((PWM_PERIOD_CYCLES) / 4)
TIM1.Pulse-PWM\ Generation4\ No\ Output=(((PWM_PERIOD_CYCLES) / 2) - (HTMIN))
TIM1.RepetitionCounter=(REP_COUNTER)
TIM1.TIM_MasterOutputTrigger=TIM_TRGO_UPDATE
TIM2.Period=M1_HALL_TIM_PERIOD
USART2.BaudRate=115200
USART2.VirtualMode=VM_ASYNC
USART2.VirtualMode-Asynchronous=VM_ASYNC
USART2.WordLength=WORDLENGTH_8B
VP_MotorControl_MC_ENABLED.Mode=Enabled
VP_TIM1_VS_ClockSourceITR.Mode=TriggerSource_ITR1
VP_TIM1_VS_ControllerModeTrigger.Mode=Trigger Mode
VP_TIM1_VS_no_output4.Mode=PWM Generation4 No Output
VP_TIM2_VS_ClockSourceINT.Mode=Internal
board=custom

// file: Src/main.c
/* USER CODE BEGIN Header */
/**
  ******************************************************************************
  * @file           : main.c
  * @brief          : Main program body
  ******************************************************************************
  * @attention
  *
  * <h2><center>&copy; Copyright (c) 2021 STMicroelectronics.
  * All rights reserved.</center></h2>
  *
  * This software component is licensed by ST under Ultimate Liberty license
  * SLA0044, the "License"; You may not use this file except in compliance with
  * the License. You may obtain a copy of the License at:
  *                             www.st.com/SLA0044
  *
  ******************************************************************************
  */
/* USER CODE END Header */
#include "main.h"

/* USER CODE BEGIN Includes */
#include <string.h>
#include <stdio.h>
#include "regular_conversion_manager.h"
#include "math.h"
#include "mc_config.h"
/* USER CODE END Includes */

/* USER CODE BEGIN PD */

//Motor/vehicle parameters
#define NMAX 4000.0 //Max motor velocity, [RPM, float]
#define IRMSMAX 4.0 //Max motor RMS phase current, [A, float]
#define IMAXP 1.0 //Max motor current (discharge), [% decimal (0.0-1.0), float]
#define IREGENMAXP 1.0 //Max regen current, [% decimal (0.0-1.0), float]
#define IREGENMAX 8.0 //Max battery (DC) regen current, [A, float]
#define WHEELRAD 0.004 //Wheel radius, [m, float]
#define CARMASS 5.0 //Best approximation of vehicle mass, [kg, float]
#define VBUSMIN 6.0 //Minimum acceptable DC voltage, [V, float]
#define CANTXBASEID 0x500 //Starting CAN ID for outbound transmission, default to 0x500 to match Tritium, [Hex int]
#define CANRXBASEID 0x400 //Starting CAN ID for inbound recieving, default to 0x400 to match Tritium, [Hex int]

//Controller parameters
#define ISENSORGAIN 0.077 //Current sensor gain, [V/A, float]
#define MOTORSPINUPTIME 2000 //Time to allow motor to start spinning upon restart, [ms, int]
#define SPEEDRAMPTIME 150 //Ramp time for speed control command, can be 0 but may cause current surges, [ms, int]
#define TORQUERAMPTIME 150 //Ramp time for torque control command, can be 0 but may cause current surges, [ms, int]
#define FANMAXTEMPERATURE 75.0 //MOSFET temperature at which fans should be at 100% speed, can be increased to reduce LV power consumption, [degC, float]
#define FANMINTEMPERATURE 0.0 //MOSFET temperature at which fans should be at 0% speed (off), can be increased to reduce LV power consumption, [degC, float]

//Firmware parameters
#define NTOL 10.0 //Motor velocity logic tolerance, [RPM, float]
#define ITOLP 0.10 //Motor current logic tolerance, [% decimal (0.0-1.0), float]
#define WDTIMERLIM 2000 //Watchdog timeout limit, [ms, int]

//Constants
#define PI 3.14 //Pi, [unitless, float]

//Calculated constants
#define S16ACONVFACTOR 65536.0*ISENSORGAIN/3.3 //(1529) Conversion factor for A-to-s16A, [s16A/A]
#define S16ACONVFACTORINV 3.3/(65536.0*ISENSORGAIN) //(0.0006539) Conversion factor for s16A-to-A, [A/s16A]
#define IQLIM 1.414*IRMSMAX //(0.9898) Max Iq current = peak phase current, [A]
#define IQMAXS16A IQLIM*S16ACONVFACTOR //(1513.576) Max Iq current in s16A units, [s16A]
#define WMAX NMAX*PI/30.0 //Max motor velocity, [rad/s]
#define WTOL NTOL*PI/30.0 //Motor velocity logic tolerance, [rad/s]
#define VMAX WMAX*WHEELRAD //Max vehicle velocity, [m/s]
#define VTOL WTOL*WHEELRAD //Vehicle velocity logic tolerance, [m/s]
#define FANPWMSLOPE 1.0/(FANMAXTEMPERATURE - FANMINTEMPERATURE) //Linear slope for fan speed determination, [% decimal (0.0-1.0)/degC, float]

/* USER CODE END PD */

ADC_HandleTypeDef hadc1;
ADC_HandleTypeDef hadc2;

CAN_HandleTypeDef hcan1;

TIM_HandleTypeDef htim1;
TIM_HandleTypeDef htim2;

UART_HandleTypeDef huart2;

/* USER CODE BEGIN PV */

// ************************* GLOBAL VARIABLES ************************* //

// ***** Global usage ***** //
uint16_t state = 0; // State tracker
uint16_t currentWDTime = 0; //Watchdog timer for CAN timeout
uint16_t lastWDTime = 0; //Watchdog timer for CAN timeout
int userDirectionFlag = 0; //Flag for setpoint forward/reverse. 1 if forward, -1 if reverse, 0 if stopped
int mtrDirectionFlag = 0; //Flag for current direction of motor rotation. 1 if forward, -1 if reverse, 0 if stopped
int motorSpinupFlag = 0; //Flag for if motor is ramping up to speed
float fanDutyCycle = 0; //Fan duty cycle for PWM output
uint16_t delayTimer = 0;
char msg_debug[327]; // Serial debug msg

// ***** CAN variables ***** //
union {
	float test_float;
	uint32_t test_int;
}
CANTx_test;

union {
	float current_float;
	uint32_t current_int;
}
CANRx_current;

union {
	float velocity_float;
	uint32_t velocity_int;
}
CANRx_velocity;

union {
	float busVoltage_float;
	uint32_t busVoltage_int;
}
CANTx_busVoltage;

union {
	float busCurrent_float;
	uint32_t busCurrent_int;
}
CANTx_busCurrent;

union {
	float mtrVelocity_float;
	uint32_t mtrVelocity_int;
}
CANTx_mtrVelocity;

union {
	float carVelocity_float;
	uint32_t carVelocity_int;
}
CANTx_carVelocity;

union {
	float phaseCurrent_float;
	uint32_t phaseCurrent_int;
}
CANTx_phaseCurrent;

union {
	float mtrTemp_float;
	uint32_t mtrTemp_int;
}
CANTx_mtrTemp;

union {
	float FETTemp_float;
	uint32_t FETTemp_int;
}
CANTx_FETTemp;

/*
 * CANTx_ErrorFlags bits:
 * (Brackets indicate Tritium designation if different from this controller)
 *  5 - DC bus under-voltage (Bus voltage lower limit)
 *  6 - FET over-temperature (Heatsink temperature limiter)
 * 16 - Motor over-current (Hardware over current)
 * 18 - DC bus over voltage
 * 19 - Motor control error (Bad motor position hall sequence)
 * 20 - Communication fault (Watchdog caused last reset)
 * 22 - Motor over-temperature (15V under voltage)
 *
 *  0 - UNUSED (Bridge PWM limit)
 *  1 - UNUSED (Motor current limit)
 *  2 - UNUSED (Velocity limit)
 *  3 - UNUSED (Bus current limit))
 *  4 - UNUSED (Bus voltage upper limit)
 * 17 - UNUSED (Software over current)
 * 21 - UNUSED (Config read error)
 *  7-15 - Reserved
 * 23-31 - Reserved
 */
uint32_t CANTx_ErrorFlags = 0;

/*
 * @brief Header for receiving message.
 * Fields:
 * StdId - Standard ID of received message - will depend on filter parameters
 * ExtId - Extended ID of received message - will be 0 since we do not use it currently
 * IDE - Type of ID of received message - will be CAN_ID_STD or CAN_ID_EXT
 * RTR - Remote transmission request - will be CAN_RTR_DATA or CAN_RTR_REMOTE but we don't use remote
 * DLC - Data length in bytes - should be 8 for this controller
 * Timestamp
 * FilterMatchIndex - ??
 */
CAN_RxHeaderTypeDef CANRxHeader;
/*
 * @brief Header for sending message.
 * Fields:
 * StdId - Standard ID of received message - will depend on filter parameters
 * ExtId - Extended ID of received message - will be 0 since we do not use it currently
 * IDE - Type of ID of received message - will be CAN_ID_STD or CAN_ID_EXT
 * RTR - Remote transmission request - will be CAN_RTR_DATA or CAN_RTR_REMOTE but we don't use remote
 * DLC - Data length in bytes - should be 8 for this controller
 * Timestamp
 */
CAN_TxHeaderTypeDef CANTxHeader;

uint8_t CANRxData[8];
uint8_t CANTxData[8];
uint32_t CANTxMailbox;

// ***** ADC variables ***** //
RegConv_t Pot1Conv;
uint8_t Pot1Handle;
uint16_t pot1_value;

RegConv_t Pot2Conv;
uint8_t Pot2Handle;
uint16_t pot2_value;

RegConv_t DCCurrConv;
uint8_t DCCurrHandle;
uint16_t DCCurr_value;

RegConv_t ThermAHConv;
uint8_t ThermAHHandle;

RegConv_t ThermALConv;
uint8_t ThermALHandle;
uint16_t thermAL_temp;

RegConv_t ThermBHConv;
uint8_t ThermBHHandle;
uint16_t thermBH_temp;

RegConv_t ThermBLConv;
uint8_t ThermBLHandle;
uint16_t thermBL_temp;

RegConv_t ThermCHConv;
uint8_t ThermCHHandle;
uint16_t thermCH_temp;

RegConv_t ThermCLConv;
uint8_t ThermCLHandle;
uint16_t thermCL_temp;

RegConv_t ThermMTRConv;
uint8_t ThermMTRHandle;

// ************************* END GLOBAL VARIABLES ************************* //

/* USER CODE END PV */

void SystemClock_Config(void);
static void MX_GPIO_Init(void);
static void MX_ADC1_Init(void);
static void MX_ADC2_Init(void);
static void MX_TIM1_Init(void);
static void MX_TIM2_Init(void);
static void MX_USART2_UART_Init(void);
static void MX_CAN1_Init(void);
static void MX_NVIC_Init(void);
/* USER CODE BEGIN PFP */

// ************************* STATE PROTOTYPES ************************* //

// 0xx states: Startup
void state000(void);
void state001(void);
void state099(void);

// 1xx states: Reading values
void state100(void);
void state101(void);
void state102(void);
void state103(void);
void state104(void);
void state105(void);
void state106(void);
void state107(void);
void state108(void);
void state109(void);
void state110(void);
void state111(void);

// 2xx states: Reading input
void state200(void);
void state201(void);
void state202(void);
void state298(void);
void state299(void);

// 3xx states: Fan control
void state300(void);
void state301(void);
void state302(void);
void state303(void);

// 4xx states: Checking faults
void state400(void);
void state401(void);
void state402(void);
void state403(void);
void state404(void);
void state405(void);
void state406(void);
void state407(void);
void state499(void);

// 5xx states: Writing drive commands
void state500(void);
void state501(void);
void state502(void);
void state503(void);
void state504(void);
void state505(void);

// 6xx states: CAN sending
void state600(void);
void state601(void); //Status information; Base + 1
void state602(void); //Bus measurement; Base + 2
void state603(void); //Velocity measurement; Base + 3
void state604(void); //Phase current measurement; Base + 4
void state605(void); //Sink & motor temperature measurement; Base + 11
void state699(void);

// ************************* END STATE PROTOYPES ************************* //

// ************************* HELPER PROTOTYPES ************************* //
void fsmInit();
void faultState();
void clearFault();
float convertTempVal(uint16_t thermXX_value);
void sendCANMessage(uint32_t LowDataByte, uint32_t HighDataByte, int IDBonus);
void printState();
void printNum(int num);
// ************************* END HELPER PROTOTYPES ************************* //
/* USER CODE END PFP */

/* USER CODE BEGIN 0 */

//CAN data receiver
void HAL_CAN_RxFifo0MsgPendingCallback(CAN_HandleTypeDef *hcan)
{
	HAL_CAN_GetRxMessage(hcan, CAN_RX_FIFO0, &CANRxHeader, CANRxData);

	if (CANRxHeader.StdId == CANRXBASEID + 1)
	{
		CANRx_velocity.velocity_int = CANRxData[0] | (CANRxData[1] << 8) | (CANRxData[2] << 16) | (CANRxData[3] << 24);
		CANRx_current.current_int   = CANRxData[4] | (CANRxData[5] << 8) | (CANRxData[6] << 16) | (CANRxData[7] << 24);
	}
}

/* USER CODE END 0 */

int main(void)
{

  /* MCU Configuration--------------------------------------------------------*/

  /* Reset of all peripherals, Initializes the Flash interface and the Systick. */
  HAL_Init();

  /* USER CODE BEGIN Init */
  fsmInit();
  /* USER CODE END Init */

  /* Configure the system clock */
  SystemClock_Config();

  /* Initialize all configured peripherals */
  MX_GPIO_Init();
  MX_ADC1_Init();
  MX_ADC2_Init();
  MX_TIM1_Init();
  MX_TIM2_Init();
  MX_USART2_UART_Init();
//  MX_MotorControl_Init();
  MX_CAN1_Init();

  /* Initialize interrupts */
  MX_NVIC_Init();
  /* USER CODE BEGIN 2 */
  HAL_CAN_Start(&hcan1);
  HAL_CAN_ActivateNotification(&hcan1, CAN_IT_RX_FIFO0_MSG_PENDING);

  CANTxHeader.DLC = 8;  // data length
  CANTxHeader.IDE = CAN_ID_STD;
  CANTxHeader.RTR = CAN_RTR_DATA;
  CANTxHeader.StdId = CANTXBASEID;  // ID

  state000();
  /* USER CODE END 2 */

  /* Infinite loop */
  /* USER CODE BEGIN WHILE */
  while (1)
  {
	  switch (state)
	  {
	  	  case 0: state000(); break;
	  	  case 1: state001(); break;
  	  	  case 99: state099(); break;

	  	  case 100: state100(); break;
	  	  case 101: state101(); break;
	  	  case 102: state102(); break;
	  	  case 103: state103(); break;
	  	  case 104: state104(); break;
	  	  case 105: state105(); break;
	  	  case 106: state106(); break;
	  	  case 107: state107(); break;
	  	  case 108: state108(); break;
	  	  case 109: state109(); break;
	  	  case 110: state110(); break;
	  	  case 111: state111(); break;

	  	  case 200: state200(); break;
	  	  case 201: state201(); break;
	  	  case 202: state202(); break;
	  	  case 298: state298(); break;
	  	  case 299: state299(); break;

	  	  case 300: state300(); break;
	  	  case 301: state301(); break;
	  	  case 302: state302(); break;
	  	  case 303: state303(); break;

	  	  case 400: state400(); break;
	  	  case 401: state401(); break;
	  	  case 402: state402(); break;
	  	  case 403: state403(); break;
	  	  case 404: state404(); break;
	  	  case 405: state405(); break;
	  	  case 406: state406(); break;
	  	  case 407: state407(); break;
	  	  case 499: state499(); break;

	  	  case 500: state500(); break;
	  	  case 501: state501(); break;
	  	  case 502: state502(); break;
	  	  case 503: state503(); break;
	  	  case 504: state504(); break;
	  	  case 505: state505(); break;

	  	  case 600: state600(); break;
	  	  case 601: state601(); break;
	  	  case 602: state602(); break;
	  	  case 603: state603(); break;
	  	  case 604: state604(); break;
	  	  case 605: state605(); break;
	  	  case 699: state699(); break;
	  }
    /* USER CODE END WHILE */

    /* USER CODE BEGIN 3 */
	  sprintf(msg_debug, "car velocity (float 100x m/s): %lu\r\n", (uint32_t) (100.0*CANRx_velocity.velocity_float));
	  HAL_UART_Transmit(&huart2, (uint8_t*)msg_debug, strlen(msg_debug), HAL_MAX_DELAY);

	  sprintf(msg_debug, "mtr current (float perc): %lu\r\n", (uint32_t) (100.0*CANRx_current.current_float));
	  HAL_UART_Transmit(&huart2, (uint8_t*)msg_debug, strlen(msg_debug), HAL_MAX_DELAY);

	  printState();
  }
  /* USER CODE END 3 */
}

void SystemClock_Config(void)
{
  RCC_OscInitTypeDef RCC_OscInitStruct = {0};
  RCC_ClkInitTypeDef RCC_ClkInitStruct = {0};

  /** Configure the main internal regulator output voltage
  */
  __HAL_RCC_PWR_CLK_ENABLE();
  __HAL_PWR_VOLTAGESCALING_CONFIG(PWR_REGULATOR_VOLTAGE_SCALE1);

  /** Initializes the RCC Oscillators according to the specified parameters
  * in the RCC_OscInitTypeDef structure.
  */
  RCC_OscInitStruct.OscillatorType = RCC_OSCILLATORTYPE_HSE;
  RCC_OscInitStruct.HSEState = RCC_HSE_ON;
  RCC_OscInitStruct.PLL.PLLState = RCC_PLL_ON;
  RCC_OscInitStruct.PLL.PLLSource = RCC_PLLSOURCE_HSE;
  RCC_OscInitStruct.PLL.PLLM = 4;
  RCC_OscInitStruct.PLL.PLLN = 180;
  RCC_OscInitStruct.PLL.PLLP = RCC_PLLP_DIV2;
  RCC_OscInitStruct.PLL.PLLQ = 2;
  RCC_OscInitStruct.PLL.PLLR = 2;
  if (HAL_RCC_OscConfig(&RCC_OscInitStruct) != HAL_OK)
  {
    Error_Handler();
  }

  /** Activate the Over-Drive mode
  */
  if (HAL_PWREx_EnableOverDrive() != HAL_OK)
  {
    Error_Handler();
  }

  /** Initializes the CPU, AHB and APB buses clocks
  */
  RCC_ClkInitStruct.ClockType = RCC_CLOCKTYPE_HCLK|RCC_CLOCKTYPE_SYSCLK
                              |RCC_CLOCKTYPE_PCLK1|RCC_CLOCKTYPE_PCLK2;
  RCC_ClkInitStruct.SYSCLKSource = RCC_SYSCLKSOURCE_PLLCLK;
  RCC_ClkInitStruct.AHBCLKDivider = RCC_SYSCLK_DIV1;
  RCC_ClkInitStruct.APB1CLKDivider = RCC_HCLK_DIV4;
  RCC_ClkInitStruct.APB2CLKDivider = RCC_HCLK_DIV2;

  if (HAL_RCC_ClockConfig(&RCC_ClkInitStruct, FLASH_LATENCY_5) != HAL_OK)
  {
    Error_Handler();
  }
}

/**
  * @brief NVIC Configuration.
  * @retval None
  */
static void MX_NVIC_Init(void)
{
  /* ADC_IRQn interrupt configuration */
  HAL_NVIC_SetPriority(ADC_IRQn, 2, 0);
  HAL_NVIC_EnableIRQ(ADC_IRQn);
  /* TIM1_UP_TIM10_IRQn interrupt configuration */
  HAL_NVIC_SetPriority(TIM1_UP_TIM10_IRQn, 0, 0);
  HAL_NVIC_EnableIRQ(TIM1_UP_TIM10_IRQn);
  /* TIM1_BRK_TIM9_IRQn interrupt configuration */
  HAL_NVIC_SetPriority(TIM1_BRK_TIM9_IRQn, 4, 1);
  HAL_NVIC_EnableIRQ(TIM1_BRK_TIM9_IRQn);
  /* TIM2_IRQn interrupt configuration */
  HAL_NVIC_SetPriority(TIM2_IRQn, 3, 0);
  HAL_NVIC_EnableIRQ(TIM2_IRQn);
  /* USART2_IRQn interrupt configuration */
  HAL_NVIC_SetPriority(USART2_IRQn, 3, 1);
  HAL_NVIC_EnableIRQ(USART2_IRQn);
}

static void MX_ADC1_Init(void)
{

  ADC_InjectionConfTypeDef sConfigInjected = {0};
  ADC_ChannelConfTypeDef sConfig = {0};

  /** Configure the global features of the ADC (Clock, Resolution, Data Alignment and number of conversion)
  */
  hadc1.Instance = ADC1;
  hadc1.Init.ClockPrescaler = ADC_CLOCK_SYNC_PCLK_DIV4;
  hadc1.Init.Resolution = ADC_RESOLUTION_12B;
  hadc1.Init.ScanConvMode = ENABLE;
  hadc1.Init.ContinuousConvMode = DISABLE;
  hadc1.Init.DiscontinuousConvMode = DISABLE;
  hadc1.Init.ExternalTrigConvEdge = ADC_EXTERNALTRIGCONVEDGE_NONE;
  hadc1.Init.ExternalTrigConv = ADC_SOFTWARE_START;
  hadc1.Init.DataAlign = ADC_DATAALIGN_LEFT;
  hadc1.Init.NbrOfConversion = 2;
  hadc1.Init.DMAContinuousRequests = DISABLE;
  hadc1.Init.EOCSelection = ADC_EOC_SINGLE_CONV;
  if (HAL_ADC_Init(&hadc1) != HAL_OK)
  {
    Error_Handler();
  }

  /** Configures for the selected ADC injected channel its corresponding rank in the sequencer and its sample time
  */
  sConfigInjected.InjectedChannel = ADC_CHANNEL_1;
  sConfigInjected.InjectedRank = 1;
  sConfigInjected.InjectedNbrOfConversion = 1;
  sConfigInjected.InjectedSamplingTime = ADC_SAMPLETIME_15CYCLES;
  sConfigInjected.ExternalTrigInjecConvEdge = ADC_EXTERNALTRIGINJECCONVEDGE_RISING;
  sConfigInjected.ExternalTrigInjecConv = ADC_EXTERNALTRIGINJECCONV_T1_CC4;
  sConfigInjected.AutoInjectedConv = DISABLE;
  sConfigInjected.InjectedDiscontinuousConvMode = DISABLE;
  sConfigInjected.InjectedOffset = 0;
  if (HAL_ADCEx_InjectedConfigChannel(&hadc1, &sConfigInjected) != HAL_OK)
  {
    Error_Handler();
  }

  /** Configure for the selected ADC regular channel its corresponding rank in the sequencer and its sample time.
  */
  sConfig.Channel = ADC_CHANNEL_15;
  sConfig.Rank = 1;
  sConfig.SamplingTime = ADC_SAMPLETIME_3CYCLES;
  if (HAL_ADC_ConfigChannel(&hadc1, &sConfig) != HAL_OK)
  {
    Error_Handler();
  }

  /** Configure for the selected ADC regular channel its corresponding rank in the sequencer and its sample time.
  */
  sConfig.Channel = ADC_CHANNEL_14;
  sConfig.Rank = 2;
  sConfig.SamplingTime = ADC_SAMPLETIME_28CYCLES;
  if (HAL_ADC_ConfigChannel(&hadc1, &sConfig) != HAL_OK)
  {
    Error_Handler();
  }

}

static void MX_ADC2_Init(void)
{

  ADC_InjectionConfTypeDef sConfigInjected = {0};
  ADC_ChannelConfTypeDef sConfig = {0};

  /** Configure the global features of the ADC (Clock, Resolution, Data Alignment and number of conversion)
  */
  hadc2.Instance = ADC2;
  hadc2.Init.ClockPrescaler = ADC_CLOCK_SYNC_PCLK_DIV4;
  hadc2.Init.Resolution = ADC_RESOLUTION_12B;
  hadc2.Init.ScanConvMode = ENABLE;
  hadc2.Init.ContinuousConvMode = DISABLE;
  hadc2.Init.DiscontinuousConvMode = DISABLE;
  hadc2.Init.ExternalTrigConvEdge = ADC_EXTERNALTRIGCONVEDGE_NONE;
  hadc2.Init.ExternalTrigConv = ADC_SOFTWARE_START;
  hadc2.Init.DataAlign = ADC_DATAALIGN_LEFT;
  hadc2.Init.NbrOfConversion = 1;
  hadc2.Init.DMAContinuousRequests = DISABLE;
  hadc2.Init.EOCSelection = ADC_EOC_SINGLE_CONV;
  if (HAL_ADC_Init(&hadc2) != HAL_OK)
  {
    Error_Handler();
  }

  /** Configures for the selected ADC injected channel its corresponding rank in the sequencer and its sample time
  */
  sConfigInjected.InjectedChannel = ADC_CHANNEL_4;
  sConfigInjected.InjectedRank = 1;
  sConfigInjected.InjectedNbrOfConversion = 1;
  sConfigInjected.InjectedSamplingTime = ADC_SAMPLETIME_15CYCLES;
  sConfigInjected.ExternalTrigInjecConvEdge = ADC_EXTERNALTRIGINJECCONVEDGE_RISING;
  sConfigInjected.ExternalTrigInjecConv = ADC_EXTERNALTRIGINJECCONV_T1_CC4;
  sConfigInjected.AutoInjectedConv = DISABLE;
  sConfigInjected.InjectedDiscontinuousConvMode = DISABLE;
  sConfigInjected.InjectedOffset = 0;
  if (HAL_ADCEx_InjectedConfigChannel(&hadc2, &sConfigInjected) != HAL_OK)
  {
    Error_Handler();
  }

  /** Configure for the selected ADC regular channel its corresponding rank in the sequencer and its sample time.
  */
  sConfig.Channel = ADC_CHANNEL_4;
  sConfig.Rank = 1;
  sConfig.SamplingTime = ADC_SAMPLETIME_15CYCLES;
  if (HAL_ADC_ConfigChannel(&hadc2, &sConfig) != HAL_OK)
  {
    Error_Handler();
  }

}

static void MX_CAN1_Init(void)
{

  hcan1.Instance = CAN1;
  hcan1.Init.Prescaler = 18;
  hcan1.Init.Mode = CAN_MODE_NORMAL;
  hcan1.Init.SyncJumpWidth = CAN_SJW_1TQ;
  hcan1.Init.TimeSeg1 = CAN_BS1_2TQ;
  hcan1.Init.TimeSeg2 = CAN_BS2_2TQ;
  hcan1.Init.TimeTriggeredMode = DISABLE;
  hcan1.Init.AutoBusOff = DISABLE;
  hcan1.Init.AutoWakeUp = DISABLE;
  hcan1.Init.AutoRetransmission = DISABLE;
  hcan1.Init.ReceiveFifoLocked = DISABLE;
  hcan1.Init.TransmitFifoPriority = DISABLE;
  if (HAL_CAN_Init(&hcan1) != HAL_OK)
  {
    Error_Handler();
  }
  /* USER CODE BEGIN CAN1_Init 2 */

  CAN_FilterTypeDef canfilterconfig;

  canfilterconfig.FilterActivation = CAN_FILTER_ENABLE; //Always enable
  canfilterconfig.FilterBank = 18; //Anything between 0-SlaveStartFilterBank
  canfilterconfig.FilterFIFOAssignment = CAN_RX_FIFO0; //FIFO stack for incoming data, can be FIFO0 or 1
  canfilterconfig.FilterIdHigh = CANRXBASEID<<5;
  canfilterconfig.FilterIdLow = 0;
  canfilterconfig.FilterMaskIdHigh = 0; //0xFFC<<5; //Binary of FFC: 111111111100 -> compare all bits with CANRXBASEID + 1-3 except last 2
  canfilterconfig.FilterMaskIdLow = 0x0000;
  canfilterconfig.FilterMode = CAN_FILTERMODE_IDMASK; //Can be mask or list. Mask: looks for particular bits in the identifier. List:
  canfilterconfig.FilterScale = CAN_FILTERSCALE_32BIT; //Means ID is 32 bits wide
  canfilterconfig.SlaveStartFilterBank = 20; //0-13: CAN1, 14-27: CAN2. Meaningless if there is only 1

  HAL_CAN_ConfigFilter(&hcan1, &canfilterconfig);

	/*
	 * Filter calcs:
	  	Mask: which bits of received ID to compare with filter ID
		Ref: 23:00, https://www.youtube.com/watch?v=JfWlIY0zAIc&t=0s
		Incoming IDs:
		- Base + 1: 0x400 + 1 = 0x401 = 010000000001
		- Base + 2: 0x400 + 2 = 0x402 = 010000000010
		- Base + 3: 0x400 + 3 = 0x403 = 010000000011
		Filter ID:
		- Base + 0: 0x400 + 0 = 0x400 = 010000000000
		Mask:
		- Mask + 0: 0xFFC + 0 = 0xFFC = 111111111100
	 */
  /* USER CODE END CAN1_Init 2 */

}

static void MX_TIM1_Init(void)
{

  TIM_SlaveConfigTypeDef sSlaveConfig = {0};
  TIM_MasterConfigTypeDef sMasterConfig = {0};
  TIM_OC_InitTypeDef sConfigOC = {0};
  TIM_BreakDeadTimeConfigTypeDef sBreakDeadTimeConfig = {0};

  htim1.Instance = TIM1;
  htim1.Init.Prescaler = ((TIM_CLOCK_DIVIDER) - 1);
  htim1.Init.CounterMode = TIM_COUNTERMODE_CENTERALIGNED1;
  htim1.Init.Period = ((PWM_PERIOD_CYCLES) / 2);
  htim1.Init.ClockDivision = TIM_CLOCKDIVISION_DIV2;
  htim1.Init.RepetitionCounter = (REP_COUNTER);
  htim1.Init.AutoReloadPreload = TIM_AUTORELOAD_PRELOAD_DISABLE;
  if (HAL_TIM_Base_Init(&htim1) != HAL_OK)
  {
    Error_Handler();
  }
  if (HAL_TIM_PWM_Init(&htim1) != HAL_OK)
  {
    Error_Handler();
  }
  sSlaveConfig.SlaveMode = TIM_SLAVEMODE_TRIGGER;
  sSlaveConfig.InputTrigger = TIM_TS_ITR1;
  if (HAL_TIM_SlaveConfigSynchro(&htim1, &sSlaveConfig) != HAL_OK)
  {
    Error_Handler();
  }
  sMasterConfig.MasterOutputTrigger = TIM_TRGO_UPDATE;
  sMasterConfig.MasterSlaveMode = TIM_MASTERSLAVEMODE_DISABLE;
  if (HAL_TIMEx_MasterConfigSynchronization(&htim1, &sMasterConfig) != HAL_OK)
  {
    Error_Handler();
  }
  sConfigOC.OCMode = TIM_OCMODE_PWM1;
  sConfigOC.Pulse = 0;
  sConfigOC.OCPolarity = TIM_OCPOLARITY_HIGH;
  sConfigOC.OCNPolarity = TIM_OCNPOLARITY_HIGH;
  sConfigOC.OCFastMode = TIM_OCFAST_DISABLE;
  sConfigOC.OCIdleState = TIM_OCIDLESTATE_RESET;
  sConfigOC.OCNIdleState = TIM_OCNIDLESTATE_RESET;
  if (HAL_TIM_PWM_ConfigChannel(&htim1, &sConfigOC, TIM_CHANNEL_1) != HAL_OK)
  {
    Error_Handler();
  }
  if (HAL_TIM_PWM_ConfigChannel(&htim1, &sConfigOC, TIM_CHANNEL_2) != HAL_OK)
  {
    Error_Handler();
  }
  if (HAL_TIM_PWM_ConfigChannel(&htim1, &sConfigOC, TIM_CHANNEL_3) != HAL_OK)
  {
    Error_Handler();
  }
  sConfigOC.OCMode = TIM_OCMODE_PWM2;
  sConfigOC.Pulse = (((PWM_PERIOD_CYCLES) / 2) - (HTMIN));
  if (HAL_TIM_PWM_ConfigChannel(&htim1, &sConfigOC, TIM_CHANNEL_4) != HAL_OK)
  {
    Error_Handler();
  }
  sBreakDeadTimeConfig.OffStateRunMode = TIM_OSSR_ENABLE;
  sBreakDeadTimeConfig.OffStateIDLEMode = TIM_OSSI_ENABLE;
  sBreakDeadTimeConfig.LockLevel = TIM_LOCKLEVEL_1;
  sBreakDeadTimeConfig.DeadTime = ((DEAD_TIME_COUNTS) / 2);
  sBreakDeadTimeConfig.BreakState = TIM_BREAK_ENABLE;
  sBreakDeadTimeConfig.BreakPolarity = TIM_BREAKPOLARITY_HIGH;
  sBreakDeadTimeConfig.AutomaticOutput = TIM_AUTOMATICOUTPUT_DISABLE;
  if (HAL_TIMEx_ConfigBreakDeadTime(&htim1, &sBreakDeadTimeConfig) != HAL_OK)
  {
    Error_Handler();
  }
  HAL_TIM_MspPostInit(&htim1);

}

static void MX_TIM2_Init(void)
{

  TIM_ClockConfigTypeDef sClockSourceConfig = {0};
  TIM_MasterConfigTypeDef sMasterConfig = {0};

  htim2.Instance = TIM2;
  htim2.Init.Prescaler = 0;
  htim2.Init.CounterMode = TIM_COUNTERMODE_UP;
//  htim2.Init.Period = M1_HALL_TIM_PERIOD;
  htim2.Init.ClockDivision = TIM_CLOCKDIVISION_DIV1;
  htim2.Init.AutoReloadPreload = TIM_AUTORELOAD_PRELOAD_DISABLE;
  if (HAL_TIM_Base_Init(&htim2) != HAL_OK)
  {
    Error_Handler();
  }
  sClockSourceConfig.ClockSource = TIM_CLOCKSOURCE_INTERNAL;
  if (HAL_TIM_ConfigClockSource(&htim2, &sClockSourceConfig) != HAL_OK)
  {
    Error_Handler();
  }
  sMasterConfig.MasterOutputTrigger = TIM_TRGO_RESET;
  sMasterConfig.MasterSlaveMode = TIM_MASTERSLAVEMODE_DISABLE;
  if (HAL_TIMEx_MasterConfigSynchronization(&htim2, &sMasterConfig) != HAL_OK)
  {
    Error_Handler();
  }

}

static void MX_USART2_UART_Init(void)
{

  huart2.Instance = USART2;
  huart2.Init.BaudRate = 115200;
  huart2.Init.WordLength = UART_WORDLENGTH_8B;
  huart2.Init.StopBits = UART_STOPBITS_1;
  huart2.Init.Parity = UART_PARITY_NONE;
  huart2.Init.Mode = UART_MODE_TX_RX;
  huart2.Init.HwFlowCtl = UART_HWCONTROL_NONE;
  huart2.Init.OverSampling = UART_OVERSAMPLING_16;
  if (HAL_UART_Init(&huart2) != HAL_OK)
  {
    Error_Handler();
  }

}

static void MX_GPIO_Init(void)
{
  GPIO_InitTypeDef GPIO_InitStruct = {0};

  /* GPIO Ports Clock Enable */
  __HAL_RCC_GPIOH_CLK_ENABLE();
  __HAL_RCC_GPIOC_CLK_ENABLE();
  __HAL_RCC_GPIOA_CLK_ENABLE();
  __HAL_RCC_GPIOB_CLK_ENABLE();

  /*Configure GPIO pin Output Level */
  HAL_GPIO_WritePin(DRV_DIS_GPIO_Port, DRV_DIS_Pin, GPIO_PIN_RESET);

  /*Configure GPIO pin Output Level */
  HAL_GPIO_WritePin(GPIOA, FLT_OUT_Pin|HALLA_OUT_Pin, GPIO_PIN_RESET);

  /*Configure GPIO pin Output Level */
  HAL_GPIO_WritePin(GPIO_OUT_GPIO_Port, GPIO_OUT_Pin, GPIO_PIN_RESET);

  /*Configure GPIO pin : DRV_DIS_Pin */
  GPIO_InitStruct.Pin = DRV_DIS_Pin;
  GPIO_InitStruct.Mode = GPIO_MODE_OUTPUT_PP;
  GPIO_InitStruct.Pull = GPIO_NOPULL;
  GPIO_InitStruct.Speed = GPIO_SPEED_FREQ_LOW;
  HAL_GPIO_Init(DRV_DIS_GPIO_Port, &GPIO_InitStruct);

  /*Configure GPIO pins : MTR_OC_Pin HV_OV_Pin */
  GPIO_InitStruct.Pin = MTR_OC_Pin|HV_OV_Pin;
  GPIO_InitStruct.Mode = GPIO_MODE_INPUT;
  GPIO_InitStruct.Pull = GPIO_NOPULL;
  HAL_GPIO_Init(GPIOB, &GPIO_InitStruct);

  /*Configure GPIO pin : FET_OT_Pin */
  GPIO_InitStruct.Pin = FET_OT_Pin;
  GPIO_InitStruct.Mode = GPIO_MODE_INPUT;
  GPIO_InitStruct.Pull = GPIO_NOPULL;
  HAL_GPIO_Init(FET_OT_GPIO_Port, &GPIO_InitStruct);

  /*Configure GPIO pin : MTR_OT_Pin */
  GPIO_InitStruct.Pin = MTR_OT_Pin;
  GPIO_InitStruct.Mode = GPIO_MODE_INPUT;
  GPIO_InitStruct.Pull = GPIO_NOPULL;
  HAL_GPIO_Init(MTR_OT_GPIO_Port, &GPIO_InitStruct);

  /*Configure GPIO pins : FLT_OUT_Pin HALLA_OUT_Pin */
  GPIO_InitStruct.Pin = FLT_OUT_Pin|HALLA_OUT_Pin;
  GPIO_InitStruct.Mode = GPIO_MODE_OUTPUT_PP;
  GPIO_InitStruct.Pull = GPIO_NOPULL;
  GPIO_InitStruct.Speed = GPIO_SPEED_FREQ_LOW;
  HAL_GPIO_Init(GPIOA, &GPIO_InitStruct);

  /*Configure GPIO pin : GPIO_OUT_Pin */
  GPIO_InitStruct.Pin = GPIO_OUT_Pin;
  GPIO_InitStruct.Mode = GPIO_MODE_OUTPUT_PP;
  GPIO_InitStruct.Pull = GPIO_NOPULL;
  GPIO_InitStruct.Speed = GPIO_SPEED_FREQ_LOW;
  HAL_GPIO_Init(GPIO_OUT_GPIO_Port, &GPIO_InitStruct);

}

/* USER CODE BEGIN 4 */

// ************************* STATE FUNCTIONS *************************//

//***** 0xx states: Startup *****//
/**
 * @brief Startup entrance state
 */
void state000(void)
{
	printState();
	//MC_StopMotor1(); //Make sure motor is stopped at startup
//	state = 1; //FSM mode
//	state = 99; //Workbench mode
	state = 500; //Drive commands
	printState();
}

/**
 * @brief Start start machine
 */
void state001(void)
{
	HAL_Delay(250); //Short delay to account for startup transients (DC voltage spike)
	lastWDTime = HAL_GetTick();
	state = 100;
}

/**
 * @brief Workbench mode
 */
void state099(void)
{
	printState();
}

//***** 1xx states: Reading current values *****//
/**
 * @brief Value reading entrance state
 */
void state100(void)
{
	state = 101;
}

/**
 * @brief Read DC voltage
 */
void state101(void)
{
	CANTx_busVoltage.busVoltage_float = ((float) PQD_MotorPowMeasM1.pVBS->AvBusVoltage_d) * ((float) PQD_MotorPowMeasM1.pVBS->ConversionFactor) / 65536.0;
	state = 102;
}

/**
 * @brief Read DC current
 */
void state102(void)
{
	if (RCM_GetUserConvState() == RCM_USERCONV_IDLE)
	{
		//if Idle, then program a new conversion request
		RCM_RequestUserConv(DCCurrHandle);
	}
	else if (RCM_GetUserConvState() == RCM_USERCONV_EOC)
	{
		//if Done, then read the captured value
		CANTx_busCurrent.busCurrent_float = ((RCM_GetUserConv() * 3.3 / 65535.0) - 2.5) / ISENSORGAIN;
		state = 103;
	}
}

/**
 * @brief Read motor velocity (RPM) & vehicle velocity (m/s)
 */
void state103(void)
{
	CANTx_mtrVelocity.mtrVelocity_float = (float) 6*MC_GetMecSpeedAverageMotor1(); //Multiply by 6 to convert from dHz to RPM;
	CANTx_carVelocity.carVelocity_float = CANTx_mtrVelocity.mtrVelocity_float * WHEELRAD * PI / 30.0; //[m/s]
	state = 104;
}

/**
 * @brief Read phase current
 */
void state104(void)
{
	CANTx_phaseCurrent.phaseCurrent_float = ((float) MC_GetPhaseCurrentAmplitudeMotor1()) * S16ACONVFACTORINV;
	state = 105;
}

/**
 * @brief Read motor temperature
 */
void state105(void)
{
	if (RCM_GetUserConvState() == RCM_USERCONV_IDLE)
	{
		//if Idle, then program a new conversion request
		RCM_RequestUserConv(ThermMTRHandle);
	}
	else if (RCM_GetUserConvState() == RCM_USERCONV_EOC)
	{
		//if Done, then read the captured value
		CANTx_mtrTemp.mtrTemp_float = convertTempVal(RCM_GetUserConv());
		state = 106;
	}
}

/**
 * @brief Read FET temperature AH
 */
void state106(void)
{
	if (RCM_GetUserConvState() == RCM_USERCONV_IDLE)
	{
		//if Idle, then program a new conversion request
		RCM_RequestUserConv(ThermAHHandle);
	}
	else if (RCM_GetUserConvState() == RCM_USERCONV_EOC)
	{
		//if Done, then read the captured value
		CANTx_FETTemp.FETTemp_float = convertTempVal(RCM_GetUserConv());
		state = 107;
	}
}

/**
 * @brief Read FET temperature AL
 */
void state107(void)
{
	if (RCM_GetUserConvState() == RCM_USERCONV_IDLE)
	{
		//if Idle, then program a new conversion request
		RCM_RequestUserConv(ThermALHandle);
	}
	else if (RCM_GetUserConvState() == RCM_USERCONV_EOC)
	{
		//if Done, then read the captured value
		thermAL_temp = convertTempVal(RCM_GetUserConv());
		//If greater than current FETTemp_float, replace (only store max FET temp)
		if (thermAL_temp > CANTx_FETTemp.FETTemp_float) CANTx_FETTemp.FETTemp_float = thermAL_temp;
		state = 108;
	}
}

/**
 * @brief Read FET temperature BH
 */
void state108(void)
{
	if (RCM_GetUserConvState() == RCM_USERCONV_IDLE)
	{
		//if Idle, then program a new conversion request
		RCM_RequestUserConv(ThermBHHandle);
	}
	else if (RCM_GetUserConvState() == RCM_USERCONV_EOC)
	{
		//if Done, then read the captured value
		thermBH_temp = convertTempVal(RCM_GetUserConv());
		if (thermBH_temp > CANTx_FETTemp.FETTemp_float) CANTx_FETTemp.FETTemp_float = thermBH_temp;
		state = 109;
	}
}

/**
 * @brief Read FET temperature BL
 */
void state109(void)
{
	if (RCM_GetUserConvState() == RCM_USERCONV_IDLE)
	{
		//if Idle, then program a new conversion request
		RCM_RequestUserConv(ThermBLHandle);
	}
	else if (RCM_GetUserConvState() == RCM_USERCONV_EOC)
	{
		//if Done, then read the captured value
		thermBL_temp = convertTempVal(RCM_GetUserConv());
		if (thermBL_temp > CANTx_FETTemp.FETTemp_float) CANTx_FETTemp.FETTemp_float = thermBL_temp;
		state = 110;
	}
}

/**
 * @brief Read FET temperature CH
 */
void state110(void)
{
	//TODO - enable for V2 hardware
//	if (RCM_GetUserConvState() == RCM_USERCONV_IDLE)
//	{
//		//if Idle, then program a new conversion request
//		RCM_RequestUserConv(ThermCHHandle);
//	}
//	else if (RCM_GetUserConvState() == RCM_USERCONV_EOC)
//	{
//		//if Done, then read the captured value
//		thermCH_temp = convertTempVal(RCM_GetUserConv());
//		if (thermCH_temp > CANTx_FETTemp.FETTemp_float) CANTx_FETTemp.FETTemp_float = thermCH_temp;
//		state = 111;
//	}
	state = 111;
}

/**
 * @brief Read FET temperature CL
 */
void state111(void)
{
	//TODO - enable for V2 hardware
//	if (RCM_GetUserConvState() == RCM_USERCONV_IDLE)
//	{
//		//if Idle, then program a new conversion request
//		RCM_RequestUserConv(ThermCLHandle);
//	}
//	else if (RCM_GetUserConvState() == RCM_USERCONV_EOC)
//	{
//		//if Done, then read the captured value
//		thermCL_temp = convertTempVal(RCM_GetUserConv());
//		if (thermCL_temp > CANTx_FETTemp.FETTemp_float) CANTx_FETTemp.FETTemp_float = thermCL_temp;
//		state = 200;
//	}
	state = 200;
}

//***** 2xx states: Reading user inputs *****//
/**
 * @brief Input reading entrance state
 */
void state200(void)
{
	state = 201;
}

/**
 * @brief Check watchdog
 */
void state201(void)
{
	currentWDTime = HAL_GetTick();
	state = 202; //CAN implementation
//	state = 298; //Potentiometer implementation
}

/*
 * @brief Read CAN message
 */
void state202(void)
{
	//CAN messages read via interrupt
	state = 300;
}

/**
 * @brief Read pot 1
 */
void state298(void)
{
	if (RCM_GetUserConvState() == RCM_USERCONV_IDLE)
	{
		//if Idle, then program a new conversion request
		RCM_RequestUserConv(Pot1Handle);
	}
	else if (RCM_GetUserConvState() == RCM_USERCONV_EOC)
	{
		//if Done, then read the captured value
		pot1_value = RCM_GetUserConv();

		//Scale to [m/s]
		CANRx_velocity.velocity_float = ((float) pot1_value) / 45535.0 * VMAX;
		state = 299;
	}
}

/**
 * @brief Read pot 2
 */
void state299(void)
{
	if (RCM_GetUserConvState() == RCM_USERCONV_IDLE)
	{
		//if Idle, then program a new conversion request
		RCM_RequestUserConv(Pot2Handle);
	}
	else if (RCM_GetUserConvState() == RCM_USERCONV_EOC)
	{
		//if Done, then read the captured value
		pot2_value = RCM_GetUserConv();
		//Scale to [%]
		CANRx_current.current_float = ((float) pot2_value) / 45535.0;
		state = 300;
	}
}

//***** 3xx states: Fan control *****//
/**
 * @brief Fan control entrance state
 */
void state300(void)
{
	state = 301;
}

/**
 * @brief Calculate required fan speed
 */
void state301(void)
{
	fanDutyCycle = FANPWMSLOPE * CANTx_FETTemp.FETTemp_float;
	state = 302;
}

/**
 * @brief Set PWM outputs
 */
void state302(void)
{
	state = 303;
}

/**
 * @brief
 */
void state303(void)
{
	state = 400;
}

//***** 4xx states: Checking faults *****//
/**
 * @brief Fault check entrance state
 */
void state400(void)
{
//	state = 401;
	state = 500;
}

/**
 * @brief Check MTR OT
 */
void state401(void)
{
	state = 402;
	if (HAL_GPIO_ReadPin(MTR_OT_GPIO_Port, MTR_OT_Pin) == 1)
	{
		faultState();
		CANTx_ErrorFlags |= 1<<22; //MTR OT: 22nd bit
		sprintf(msg_debug, "MOTOR OT\r\n");
		HAL_UART_Transmit(&huart2, (uint8_t*)msg_debug, strlen(msg_debug), HAL_MAX_DELAY);
	}
}

/**
 * @brief Check MTR OC
 */
void state402(void)
{
	//TODO - Swap pin read polarity for V2 hardware
	state = 403;
	if (HAL_GPIO_ReadPin(MTR_OC_GPIO_Port, MTR_OC_Pin) == 0)
	{
		faultState();
		CANTx_ErrorFlags |= 1<<16; //MTR OC: 16th bit
		sprintf(msg_debug, "MOTOR OC\r\n");
		HAL_UART_Transmit(&huart2, (uint8_t*)msg_debug, strlen(msg_debug), HAL_MAX_DELAY);
	}
}

/**
 * @brief Check HV OV
 */
void state403(void)
{
	state = 404;
	if (HAL_GPIO_ReadPin(HV_OV_GPIO_Port, HV_OV_Pin) == 1)
	{
		faultState();
		CANTx_ErrorFlags |= 1<<18; //HV OV: 18th bit
		sprintf(msg_debug, "DC BUS OV\r\n");
		HAL_UART_Transmit(&huart2, (uint8_t*)msg_debug, strlen(msg_debug), HAL_MAX_DELAY);
	}
}

/**
 * @brief Check Check FET OT
 */
void state404(void)
{
	state = 405;
	if (HAL_GPIO_ReadPin(FET_OT_GPIO_Port, FET_OT_Pin) == 1)
	{
		faultState();
		CANTx_ErrorFlags |= 1<<6; //FET OT: 6th bit
		sprintf(msg_debug, "FET OT\r\n");
		HAL_UART_Transmit(&huart2, (uint8_t*)msg_debug, strlen(msg_debug), HAL_MAX_DELAY);
	}
}

/**
 * @brief Check communication fault (soft)
 */
void state405(void)
{
	state = 406;
	if (currentWDTime - lastWDTime > WDTIMERLIM)
	{
		faultState();
		CANTx_ErrorFlags |= 1<<20; //Communication fault: 20th bit
		sprintf(msg_debug, "WD timeout\r\n");
		HAL_UART_Transmit(&huart2, (uint8_t*)msg_debug, strlen(msg_debug), HAL_MAX_DELAY);
	}
	else
	{
		lastWDTime = HAL_GetTick();
		if(((CANTx_ErrorFlags>>20) & 1) == 1) //If error flag was set but no error is still present
		{
			CANTx_ErrorFlags &= ~(1<<20); //Clear error flag bit if it was previously set
		}
	}
}

/**
 * @brief Check control fault (soft)
 */
void state406(void)
{
	state = 407;
	//TODO - extract error codes
	if (MC_GetCurrentFaultsMotor1() > 0 || MC_GetOccurredFaultsMotor1() > 0)
	{
		faultState();
		CANTx_ErrorFlags |= 1<<19; //Control fault: 19th bit
		sprintf(msg_debug, "Control fault\r\n");
		HAL_UART_Transmit(&huart2, (uint8_t*)msg_debug, strlen(msg_debug), HAL_MAX_DELAY);
	}
	else
	{
		if(((CANTx_ErrorFlags>>19) & 1) == 1) //If error flag was set but no error is still present
		{
			CANTx_ErrorFlags &= ~(1<<19); //Clear error flag bit if it was previously set
		}
	}
}

/*
 * @brief Check missing DC voltage fault (soft)
 */
void state407(void)
{
	state = 499;
	if (CANTx_busVoltage.busVoltage_float < VBUSMIN)
	{
		faultState();
		CANTx_ErrorFlags |= 1<<5; //DC undervoltage: 5th bit
		sprintf(msg_debug, "DC voltage missing\r\n");
		HAL_UART_Transmit(&huart2, (uint8_t*)msg_debug, strlen(msg_debug), HAL_MAX_DELAY);
	}
	else
	{
		if(((CANTx_ErrorFlags>>5) & 1) == 1) //If error flag was set but no error is still present
		{
			CANTx_ErrorFlags &= ~(1<<5); //Clear error flag bit if it was previously set
		}
	}
}

/**
 * @brief Fault check exit state
 */
void state499(void)
{
	state = 500;
	//If any faults have occured (soft or hard), skip command writing
	//Controller already in safe state
	if (CANTx_ErrorFlags > 0)
	{
		state = 600;
	}
	else if (CANTx_ErrorFlags == 0)
	{
		//If there is no current fault but the fault outputs were previously set, clear them
		if(HAL_GPIO_ReadPin(FLT_OUT_GPIO_Port, FLT_OUT_Pin))
		{
			clearFault();
		}
	}
}

//***** 5xx states: Writing drive commands *****//
/**
 * @brief Drive command entrance state
 */
void state500(void)
{
	state = 501;
}

/**
 * @brief Decide drive command
 */
void state501(void)
{
	//Check driver input direction
	if (CANRx_velocity.velocity_float > 0)
	{
		userDirectionFlag = 1;
	}
	else if (CANRx_velocity.velocity_float < 0)
	{
		CANRx_velocity.velocity_float = fabs(CANRx_velocity.velocity_float);
		userDirectionFlag = -1;
	}
	else
	{
		userDirectionFlag = 0;
	}

	//Check motor direction
	if (CANTx_mtrVelocity.mtrVelocity_float > 0 && CANTx_mtrVelocity.mtrVelocity_float < NMAX)
	{
		mtrDirectionFlag = 1;
	}
	else if(CANTx_mtrVelocity.mtrVelocity_float < 0 && CANTx_mtrVelocity.mtrVelocity_float > -1*NMAX)
	{
		mtrDirectionFlag = -1;
	}
	else
	{
		mtrDirectionFlag = 0;
	}

	//If motor needs to change direction, first bring to a stop

	/*
	 * Check userDirectionFlag + mtrDirectionFlag:
	 *  1 +  1 =  2 --> fwd
	 *  1 +  0 =  1 --> fwd
	 *  1 + -1 =  0 --> stop
	 *  0 +  1 =  1 --> stop
	 *  0 +  0 =  0 --> stop
	 *  0 + -1 = -1 --> stop
	 * -1 +  1 =  0 --> stop
	 * -1 +  0 = -1 --> rvrs
	 * -1 + -1 = -2 --> rvrs
	 */
	if (userDirectionFlag + mtrDirectionFlag == 0)
	{
		CANRx_velocity.velocity_float = 0;
		CANRx_current.current_float = 0;
	}

	//Default: torque control
	state = 502;

	//If I > Imax
	if (CANRx_current.current_float > IMAXP + ITOLP)
	{
		//State does not (should not) exist
		sprintf(msg_debug, "State DNE\r\n");
		HAL_UART_Transmit(&huart2, (uint8_t*)msg_debug, strlen(msg_debug), HAL_MAX_DELAY);

		CANRx_current.current_float = 0.0;
		CANRx_velocity.velocity_float = 0.0;
	}
	//If I = 0
	else if (CANRx_current.current_float <= ITOLP)
	{
		//Torque control - do nothing
		sprintf(msg_debug, "Torque ramp requested\r\n");
		HAL_UART_Transmit(&huart2, (uint8_t*)msg_debug, strlen(msg_debug), HAL_MAX_DELAY);
	}
	//If I = Imax && V <= Vmax
	else if (CANRx_current.current_float >= IMAXP - ITOLP
			&& CANRx_current.current_float <= IMAXP + ITOLP
			&& CANRx_velocity.velocity_float <= VMAX + VTOL)
	{
		//Speed control
		state = 503;
		if (CANRx_velocity.velocity_float < VTOL)
		{
			//Regen
			state = 504;
			sprintf(msg_debug, "Regen requested\r\n");
			HAL_UART_Transmit(&huart2, (uint8_t*)msg_debug, strlen(msg_debug), HAL_MAX_DELAY);
		}
	}
	//If I < Imax && V < VMax
	else if (CANRx_current.current_float < IMAXP - ITOLP
			&& CANRx_velocity.velocity_float < VMAX - VTOL)
	{
		//Speed control
		state = 503;
		sprintf(msg_debug, "Speed ramp requested\r\n");
		HAL_UART_Transmit(&huart2, (uint8_t*)msg_debug, strlen(msg_debug), HAL_MAX_DELAY);
		if (CANRx_velocity.velocity_float < VTOL)
		{
			//Regen
			state = 504;
			sprintf(msg_debug, "Regen requested\r\n");
			HAL_UART_Transmit(&huart2, (uint8_t*)msg_debug, strlen(msg_debug), HAL_MAX_DELAY);
		}
	}
}

/**
 * @brief Write torque ramp
 */
void state502(void)
{
	float finalTorque = userDirectionFlag * CANRx_current.current_float * IQMAXS16A;

	sprintf(msg_debug, "Torque ramp value: %hu\r\n", (int) finalTorque);
	HAL_UART_Transmit(&huart2, (uint8_t*)msg_debug, strlen(msg_debug), HAL_MAX_DELAY);

	MC_ProgramTorqueRampMotor1((int) finalTorque, TORQUERAMPTIME);
//	state = 505;
	state = 600;
}

/**
 * @brief Write speed ramp
 */
void state503(void)
{
	float finalSpeed = userDirectionFlag * CANRx_velocity.velocity_float * 30.0 / (PI * WHEELRAD); //RPM

	sprintf(msg_debug, "Speed ramp value (RPM): %hu\r\n", (int) finalSpeed);
	HAL_UART_Transmit(&huart2, (uint8_t*)msg_debug, strlen(msg_debug), HAL_MAX_DELAY);

	MC_ProgramSpeedRampMotor1(finalSpeed/6.0, SPEEDRAMPTIME);
//	state = 505;
	state = 600;
}

/**
 * @brief Write regen speed ramp
 */
void state504(void)
{
	float Vbat = CANTx_busVoltage.busVoltage_float; //[V]
	float vehicleSpeed = CANTx_carVelocity.carVelocity_float; //[m/s]
	float regenPower = Vbat * IREGENMAX * CANRx_current.current_float; //P = VI
	float regenEnergy = 0.5 * CARMASS * vehicleSpeed * vehicleSpeed; //1/2 mV^2
	float regenTime = regenEnergy / regenPower; //[s]
	float regenTimeMS = regenTime * 1000.0; //[ms]

	MC_ProgramSpeedRampMotor1(0, regenTimeMS);

//	state = 505;
	state = 600;
}

/**
 * @brief Set motor status
 */
void state505(void)
{
	int motorState = MC_GetSTMStateMotor1();

	int motorSpeed = (int) fabs(CANTx_mtrVelocity.mtrVelocity_float); //[RPM]

	int motorSpin = 0;
	int userSpin = 1;
	int STMSpin = 0;

	if (motorSpeed > 0 && motorSpeed < NMAX)
	{
		motorSpin = 1;
	}
	if (CANRx_velocity.velocity_float < VTOL || CANRx_current.current_float < ITOLP) userSpin = 0;
	if (!(motorState == 0 || motorState == 7)) STMSpin = 1; //States in state_machine.h

	state = 600;

	//Cases:
	//If motor is     spinning AND should     be AND STM started --> Leave
	//If motor is     spinning AND should     be AND STM stopped --> Fake state
	//If motor is     spinning AND should not be AND STM started --> Stop
	//If motor is     spinning AND should not be AND STM stopped --> Fake state
	//If Motor is not spinning AND should     be AND STM started --> Check fault
	//If Motor is not spinning AND should     be AND STM stopped --> Start
	//If motor is not spinning AND should not be AND STM started --> Stop
	//If motor is not spinning AND should not be AND STM stopped --> Leave

	if(motorSpinupFlag == 0)
	{
		if      (motorSpin == 1 && userSpin == 1 && STMSpin == 1)
		{
			//motor = spin, user = spin, STM = spin
			//Leave
			sprintf(msg_debug, "Motor spinning as expected\r\n");
			HAL_UART_Transmit(&huart2, (uint8_t*)msg_debug, strlen(msg_debug), HAL_MAX_DELAY);
		}
		else if (motorSpin == 1 && userSpin == 1 && STMSpin == 0)
		{
			//motor = spin, user = spin, STM = stop
			//Fault/panic?? State not really possible
		}
		else if (motorSpin == 1 && userSpin == 0 && STMSpin == 1)
		{
			//motor = spin, user = stop, STM = spin
			//Stop
			sprintf(msg_debug, "User says motor should not be spinning\r\n");
			HAL_UART_Transmit(&huart2, (uint8_t*)msg_debug, strlen(msg_debug), HAL_MAX_DELAY);
			MC_StopMotor1();
		}
		else if (motorSpin == 1 && userSpin == 0 && STMSpin == 0)
		{
			//motor = spin, user = stop, STM = stop
			//Fault/panic?? State not really possible
		}
		else if (motorSpin == 0 && userSpin == 1 && STMSpin == 1)
		{
			//motor = stop, user = spin, STM = spin
			//Stop motor, check DC bus, then proceed to check faults
			sprintf(msg_debug, "Motor not spinning. Stopping STM\r\n");
			HAL_UART_Transmit(&huart2, (uint8_t*)msg_debug, strlen(msg_debug), HAL_MAX_DELAY);
			MC_StopMotor1();
		}
		else if (motorSpin == 0 && userSpin == 1 && STMSpin == 0)
		{
			//motor = stop, user = spin, STM = stop
			//Start
			MC_StartMotor1();
			sprintf(msg_debug, "Motor started\r\n");
			HAL_UART_Transmit(&huart2, (uint8_t*)msg_debug, strlen(msg_debug), HAL_MAX_DELAY);
//			HAL_Delay(MOTORSPINUPTIME);
			motorSpinupFlag = 1;
			delayTimer = HAL_GetTick();
		}
		else if (motorSpin == 0 && userSpin == 0 && STMSpin == 1)
		{
			//motor = stop, user = stop, STM = spin
			//Stop
			MC_StopMotor1();
			sprintf(msg_debug, "Motor stopped\r\n");
			HAL_UART_Transmit(&huart2, (uint8_t*)msg_debug, strlen(msg_debug), HAL_MAX_DELAY);
		}
		else if (motorSpin == 0 && userSpin == 0 && STMSpin == 0)
		{
			//motor = stop, user = stop, STM = stop
			//Leave
		}
	}
	else
	{
		if (HAL_GetTick() - delayTimer >= MOTORSPINUPTIME)
		{
			motorSpinupFlag = 0;
			sprintf(msg_debug, "Spinup flag reset\r\n");
			HAL_UART_Transmit(&huart2, (uint8_t*)msg_debug, strlen(msg_debug), HAL_MAX_DELAY);
		}
	}
}

//***** 6xx states: Sending CAN messages *****//
/**
 * @brief CAN sending entrance state
 */
void state600(void)
{
	state = 601; //CAN implementation
//	state = 699; //UART implementation
}

/**
 * @brief CAN send: Status information; Base + 1
 */
void state601(void)
{
	sendCANMessage(CANTx_ErrorFlags, 0, 1);

	sprintf(msg_debug, "Error flags sent: %lu\r\n", CANTx_ErrorFlags);
	HAL_UART_Transmit(&huart2, (uint8_t*)msg_debug, strlen(msg_debug), HAL_MAX_DELAY);

	state = 602;
}

/**
 * @brief CAN send: Bus measurement; Base + 2
 */
 void state602(void)
{
	sendCANMessage(CANTx_busVoltage.busVoltage_int, CANTx_busCurrent.busCurrent_int, 2);

	sprintf(msg_debug, "10x Bus voltage sent: %lu\r\n", (uint32_t) (10.0 * CANTx_busVoltage.busVoltage_float));
	HAL_UART_Transmit(&huart2, (uint8_t*)msg_debug, strlen(msg_debug), HAL_MAX_DELAY);

	sprintf(msg_debug, "100x Bus current sent: %lu\r\n", (uint32_t) (100.0 * CANTx_busCurrent.busCurrent_float));
	HAL_UART_Transmit(&huart2, (uint8_t*)msg_debug, strlen(msg_debug), HAL_MAX_DELAY);

	state = 603;
}

/**
 * @brief CAN send: Velocity measurement; Base + 3
 */
void state603(void)
{
	sendCANMessage(CANTx_mtrVelocity.mtrVelocity_int, CANTx_carVelocity.carVelocity_int, 3);

	sprintf(msg_debug, "100x Motor velocity sent: %lu\r\n", (uint32_t) (100.0 * CANTx_mtrVelocity.mtrVelocity_float));
	HAL_UART_Transmit(&huart2, (uint8_t*)msg_debug, strlen(msg_debug), HAL_MAX_DELAY);

	sprintf(msg_debug, "100x Car velocity sent: %lu\r\n", (uint32_t) (100.0 * CANTx_carVelocity.carVelocity_float));
	HAL_UART_Transmit(&huart2, (uint8_t*)msg_debug, strlen(msg_debug), HAL_MAX_DELAY);

	state = 604;
}

/**
 * @brief CAN send: Phase current measurement; Base + 4
 */
void state604(void)
{
	sendCANMessage(CANTx_phaseCurrent.phaseCurrent_int, CANTx_phaseCurrent.phaseCurrent_int, 4);

	sprintf(msg_debug, "100x Phase current sent: %lu\r\n", (uint32_t) (100.0 * CANTx_phaseCurrent.phaseCurrent_float));
	HAL_UART_Transmit(&huart2, (uint8_t*)msg_debug, strlen(msg_debug), HAL_MAX_DELAY);

	state = 605;
}

/**
 * @brief CAN send: Sink and motor temperature measurement; Base + 11
 */
void state605(void)
{
	sendCANMessage(CANTx_mtrTemp.mtrTemp_int, CANTx_FETTemp.FETTemp_int, 11);

	sprintf(msg_debug, "10x Motor temp sent: %lu\r\n", (uint32_t) (10.0 * CANTx_mtrTemp.mtrTemp_float));
	HAL_UART_Transmit(&huart2, (uint8_t*)msg_debug, strlen(msg_debug), HAL_MAX_DELAY);

	sprintf(msg_debug, "10x FET temp sent: %lu\r\n", (uint32_t) (10.0 * CANTx_FETTemp.FETTemp_float));
	HAL_UART_Transmit(&huart2, (uint8_t*)msg_debug, strlen(msg_debug), HAL_MAX_DELAY);

	state = 0;
//	state = 100; //Normal operation
//	state = 699; //UART data dump
}

/*
 * @brief UART data dump
 */
void state699(void)
{
	sprintf(msg_debug, "100x CANRx_velocity float (m/s): %hu\r\n", (int) (CANRx_velocity.velocity_float*100.0));
	HAL_UART_Transmit(&huart2, (uint8_t*)msg_debug, strlen(msg_debug), HAL_MAX_DELAY);

	sprintf(msg_debug, "100x CANRx_current float: %hu\r\n", (int) (100.0*CANRx_current.current_float));
	HAL_UART_Transmit(&huart2, (uint8_t*)msg_debug, strlen(msg_debug), HAL_MAX_DELAY);

	sprintf(msg_debug, "100x DC current: %hu\r\n", (int) (100.0*CANTx_busCurrent.busCurrent_float));
	HAL_UART_Transmit(&huart2, (uint8_t*)msg_debug, strlen(msg_debug), HAL_MAX_DELAY);

	sprintf(msg_debug, "100x DC voltage: %hu\r\n", (int) (100.0*CANTx_busVoltage.busVoltage_float));
	HAL_UART_Transmit(&huart2, (uint8_t*)msg_debug, strlen(msg_debug), HAL_MAX_DELAY);

	sprintf(msg_debug, "Current motor speed (RPM): %hu\r\n", (int) CANTx_mtrVelocity.mtrVelocity_float);
	HAL_UART_Transmit(&huart2, (uint8_t*)msg_debug, strlen(msg_debug), HAL_MAX_DELAY);

	sprintf(msg_debug, "Current vehicle speed (m/s): %hu\r\n", (int) CANTx_carVelocity.carVelocity_float);
	HAL_UART_Transmit(&huart2, (uint8_t*)msg_debug, strlen(msg_debug), HAL_MAX_DELAY);

	sprintf(msg_debug, "100x Motor phase current: %hu\r\n", (int) (100.0*CANTx_phaseCurrent.phaseCurrent_float));
	HAL_UART_Transmit(&huart2, (uint8_t*)msg_debug, strlen(msg_debug), HAL_MAX_DELAY);

	sprintf(msg_debug, "10x Motor temp: %hu\r\n", (int) (10.0*CANTx_mtrTemp.mtrTemp_float));
	HAL_UART_Transmit(&huart2, (uint8_t*)msg_debug, strlen(msg_debug), HAL_MAX_DELAY);

	sprintf(msg_debug, "10x FET temp: %hu\r\n", (int) (10.0*CANTx_FETTemp.FETTemp_float));
	HAL_UART_Transmit(&huart2, (uint8_t*)msg_debug, strlen(msg_debug), HAL_MAX_DELAY);

	HAL_Delay(100);
	state = 000;
}

// ************************* END STATE FUNCTIONS ************************* //

// ************************* HELPER FUNCTIONS ************************* //

/*
 * @brief initialize FSM variables
 */
 void fsmInit(void)
{
	//*** ADC setup ***//
	Pot1Conv.regADC = ADC1; /* to be modify to match your ADC */
	Pot1Conv.channel = ADC_CHANNEL_8;/* to be modify to match your ADC channel */
	Pot1Conv.samplingTime = ADC_SAMPLETIME_3CYCLES; /* to be modify to match your sampling time */
	Pot1Handle = RCM_RegisterRegConv (&Pot1Conv);

	Pot2Conv.regADC = ADC1; /* to be modify to match your ADC */
	Pot2Conv.channel = ADC_CHANNEL_7;/* to be modify to match your ADC channel */
	Pot2Conv.samplingTime = ADC_SAMPLETIME_3CYCLES; /* to be modify to match your sampling time */
	Pot2Handle = RCM_RegisterRegConv (&Pot2Conv);

	DCCurrConv.regADC = ADC1;
	DCCurrConv.channel = ADC_CHANNEL_0;
	DCCurrConv.samplingTime = ADC_SAMPLETIME_3CYCLES;
	DCCurrHandle = RCM_RegisterRegConv (&DCCurrConv);

	ThermAHConv.regADC = ADC1;
	ThermAHConv.channel = ADC_CHANNEL_12;
	ThermAHConv.samplingTime = ADC_SAMPLETIME_3CYCLES;
	ThermAHHandle = RCM_RegisterRegConv (&ThermAHConv);

	ThermALConv.regADC = ADC1;
	ThermALConv.channel = ADC_CHANNEL_13;
	ThermALConv.samplingTime = ADC_SAMPLETIME_3CYCLES;
	ThermALHandle = RCM_RegisterRegConv (&ThermALConv);

	ThermBHConv.regADC = ADC1;
	ThermBHConv.channel = ADC_CHANNEL_11;
	ThermBHConv.samplingTime = ADC_SAMPLETIME_3CYCLES;
	ThermBHHandle = RCM_RegisterRegConv (&ThermBHConv);

	ThermBLConv.regADC = ADC1;
	ThermBLConv.channel = ADC_CHANNEL_10;
	ThermBLConv.samplingTime = ADC_SAMPLETIME_3CYCLES;
	ThermBLHandle = RCM_RegisterRegConv (&ThermBLConv);

	//TODO - enable for V2 hardware, fix pin assignments
//	ThermCHConv.regADC = ADC1;
//	ThermCHConv.channel = ADC_CHANNEL_12;
//	ThermCHConv.samplingTime = ADC_SAMPLETIME_3CYCLES;
//	ThermCHHandle = RCM_RegisterRegConv (&ThermCHConv);
//
//	ThermCLConv.regADC = ADC1;
//	ThermCLConv.channel = ADC_CHANNEL_12;
//	ThermCLConv.samplingTime = ADC_SAMPLETIME_3CYCLES;
//	ThermCLHandle = RCM_RegisterRegConv (&ThermCLConv);

}

/**
 * @brief Converts thermistor raw ADC value to decimal temperature
 */
float convertTempVal(uint16_t thermXX_value)
{
	thermXX_value = thermXX_value / 16.0; // Convert left-aligned to right-aligned (0-4096)
	float thermXX_voltage = thermXX_value * 3300.0 / 4096.0; //Convert to mV (to avoid decimal places)
	float thermXX_resistance = 3300.0 * 3300 / thermXX_voltage;
	thermXX_resistance = thermXX_resistance - 3300;
	float thermXX_temp = 1000.0*(log(thermXX_resistance / 10000.0) + (3435.0/298.0));
	thermXX_temp = 1000.0 * 3435.0 / thermXX_temp;
	thermXX_temp = thermXX_temp - 273.0;
	return thermXX_temp;
}

/**
 * @brief Disables the controller FETs and enters a safe state
 */
void faultState(void)
{
	MC_StopMotor1();
	HAL_GPIO_WritePin(FLT_OUT_GPIO_Port, FLT_OUT_Pin, GPIO_PIN_SET); //Set FLT_OUT high, turning on the LED
	HAL_GPIO_WritePin(DRV_DIS_GPIO_Port, DRV_DIS_Pin, GPIO_PIN_SET); //Set DRV_DIS high, disabling the FETs
	printState();
}

/*
 * @brief Clears a controller fault state, re-enabling HV functionality
 */
void clearFault(void)
{
	HAL_GPIO_WritePin(FLT_OUT_GPIO_Port, FLT_OUT_Pin, GPIO_PIN_RESET); //Set FLT_OUT low, turning off the LED
	HAL_GPIO_WritePin(DRV_DIS_GPIO_Port, DRV_DIS_Pin, GPIO_PIN_RESET); //Set DRV_DIS low, enabling the FETs
}

/*
 * @brief Sends CAN message
 */
void sendCANMessage(uint32_t LowDataByte, uint32_t HighDataByte, int IDBonus)
{
	//Add CAN data to each of the 8 bytes
	//Convert uint32_t to uint8_t[] with bit shifting
	CANTxData[0] = (LowDataByte & 0x000000ff) >>  0;
	CANTxData[1] = (LowDataByte & 0x0000ff00) >>  8;
	CANTxData[2] = (LowDataByte & 0x00ff0000) >> 16;
	CANTxData[3] = (LowDataByte & 0xff000000) >> 24;
	CANTxData[4] = (HighDataByte & 0x000000ff) >>  0;
	CANTxData[5] = (HighDataByte & 0x0000ff00) >>  8;
	CANTxData[6] = (HighDataByte & 0x00ff0000) >> 16;
	CANTxData[7] = (HighDataByte & 0xff000000) >> 24;

	//Set CAN ID
	CANTxHeader.StdId = CANTXBASEID + IDBonus;

	if( HAL_CAN_AddTxMessage(&hcan1, &CANTxHeader, CANTxData, &CANTxMailbox) != HAL_OK)
	{
		sprintf(msg_debug, "Send error\r\n");
		HAL_UART_Transmit(&huart2, (uint8_t*)msg_debug, strlen(msg_debug), HAL_MAX_DELAY);
	}

//	while(HAL_CAN_IsTxMessagePending(&hcan1, CANTxMailbox))
//	{
//		//Do nothing wait for message to send
//		sprintf(msg_debug, "Stuck sending\r\n");
//		HAL_UART_Transmit(&huart2, (uint8_t*)msg_debug, strlen(msg_debug), HAL_MAX_DELAY);
//	}

}

/**
 * @brief Soft fault - Prints the current state variable to serial
 */
void printState(void)
{
	sprintf(msg_debug, "State %hu\r\n", state);
	HAL_UART_Transmit(&huart2, (uint8_t*)msg_debug, strlen(msg_debug), HAL_MAX_DELAY);
	HAL_Delay(250);
}

/**
 * @brief Prints an integer to serial
 */
void printNum(int num)
{
	sprintf(msg_debug, "Number %hu\r\n", num);
	HAL_UART_Transmit(&huart2, (uint8_t*)msg_debug, strlen(msg_debug), HAL_MAX_DELAY);
	HAL_Delay(250);
}

// ************************* END HELPER FUNCTIONS ************************* //
/* USER CODE END 4 */

void Error_Handler(void)
{
  __disable_irq();
  while (1)
  {
  }
}
